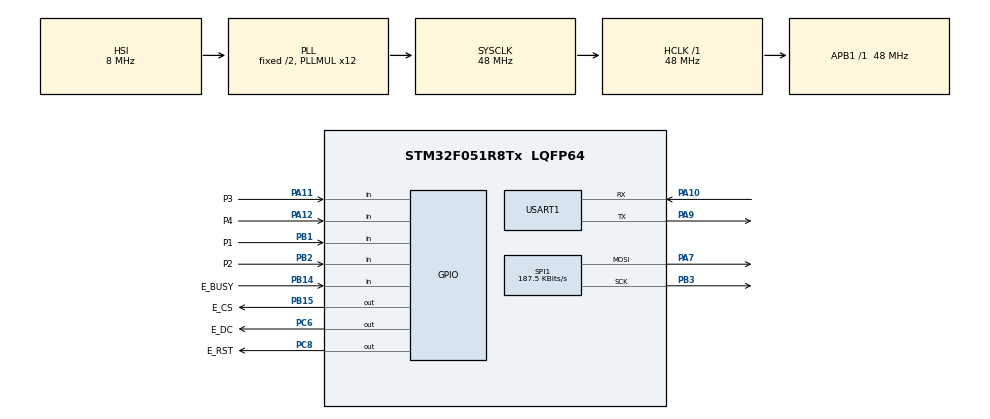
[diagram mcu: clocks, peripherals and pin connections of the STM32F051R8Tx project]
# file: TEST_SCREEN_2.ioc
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Mcu.Family=STM32F0
Mcu.Name=STM32F051R8Tx
Mcu.Package=LQFP64
PA10.Mode=Asynchronous
PA10.Signal=USART1_RX
PA11.GPIO_Label=P3
PA11.GPIO_PuPd=GPIO_PULLUP
PA11.Signal=GPIO_Input
PA12.GPIO_Label=P4
PA12.GPIO_PuPd=GPIO_PULLUP
PA12.Signal=GPIO_Input
PA13.GPIO_Label=TMS
PA13.Mode=Serial_Wire
PA13.Signal=SYS_SWDIO
PA14.GPIO_Label=SWCLK
PA14.Mode=Serial_Wire
PA14.Signal=SYS_SWCLK
PA2.Signal=USART2_TX
PA3.Signal=USART2_RX
PA7.Mode=TX_Only_Simplex_Unidirect_Master
PA7.Signal=SPI1_MOSI
PA9.Mode=Asynchronous
PA9.Signal=USART1_TX
PB1.GPIO_Label=P1
PB1.GPIO_PuPd=GPIO_PULLUP
PB1.Signal=GPIO_Input
PB14.GPIO_Label=E_BUSY
PB14.GPIO_PuPd=GPIO_PULLUP
PB14.Signal=GPIO_Input
PB15.GPIO_Label=E_CS
PB15.PinState=GPIO_PIN_SET
PB15.Signal=GPIO_Output
PB2.GPIO_Label=P2
PB2.GPIO_PuPd=GPIO_PULLUP
PB2.Signal=GPIO_Input
PB3.Mode=TX_Only_Simplex_Unidirect_Master
PB3.Signal=SPI1_SCK
PC14-OSC32_IN.Mode=LSE-External-Oscillator
PC14-OSC32_IN.Signal=RCC_OSC32_IN
PC15-OSC32_OUT.Mode=LSE-External-Oscillator
PC15-OSC32_OUT.Signal=RCC_OSC32_OUT
PC6.GPIO_Label=E_DC
PC6.Signal=GPIO_Output
PC8.GPIO_Label=E_RST
PC8.GPIO_Speed=GPIO_SPEED_FREQ_HIGH
PC8.PinState=GPIO_PIN_SET
PC8.Signal=GPIO_Output
PF0-OSC_IN.Mode=HSE-External-Oscillator
PF0-OSC_IN.Signal=RCC_OSC_IN
PF1-OSC_OUT.Mode=HSE-External-Oscillator
PF1-OSC_OUT.Signal=RCC_OSC_OUT
ProjectManager.HeapSize=0x2000
ProjectManager.StackSize=0x400
ProjectManager.TargetToolchain=STM32CubeIDE
RCC.AHBFreq_Value=48000000
RCC.APB1Freq_Value=48000000
RCC.APB1TimFreq_Value=48000000
RCC.HCLKFreq_Value=48000000
RCC.PLLMUL=RCC_PLL_MUL12
RCC.SYSCLKFreq_VALUE=48000000
RCC.SYSCLKSource=RCC_SYSCLKSOURCE_PLLCLK
SPI1.BaudRatePrescaler=SPI_BAUDRATEPRESCALER_256
SPI1.CalculateBaudRate=187.5 KBits/s
SPI1.DataSize=SPI_DATASIZE_8BIT
SPI1.Direction=SPI_DIRECTION_2LINES
SPI1.Mode=SPI_MODE_MASTER
SPI1.NSSPMode=SPI_NSS_PULSE_DISABLE
SPI1.VirtualType=VM_MASTER
USART1.VirtualMode-Asynchronous=VM_ASYNC
board=STM32F0DISCOVERY

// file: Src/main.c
/* USER CODE BEGIN Header */
/**
  ******************************************************************************
  * @file           : main.c
  * @brief          : Main program body
  ******************************************************************************
  * @attention
  *
  * <h2><center>&copy; Copyright (c) 2020 STMicroelectronics.
  * All rights reserved.</center></h2>
  *
  * This software component is licensed by ST under BSD 3-Clause license,
  * the "License"; You may not use this file except in compliance with the
  * License. You may obtain a copy of the License at:
  *                        opensource.org/licenses/BSD-3-Clause
  *
  ******************************************************************************
  */
/* USER CODE END Header */
//#include "tupian.h"

const unsigned char qie[] = {
		1,1,1,1,1,1,1,1,1,1,1,1,1,1,1,1,1,1,1,1,1,1,1,1,1,1,1,1,1,1,1,1,1,1,1,1,1,1,1,1,1,1,1,1,1,1,1,1,1,1,1,1,1,1,1,1,1,1,1,1,1,1,1,1,1,1,1,1,1,1,1,1,1,1,1,1,1,1,1,1,1,1,1,1,1,1,1,1,1,1,1,1,1,1,1,1,1,1,1,1,1,1,1,1,1,1,1,1,1,1,1,1,1,1,1,1,1,1,1,1,1,1,1,1,1,1,1,1,
		1,1,1,1,1,1,1,1,1,1,1,1,1,1,1,1,1,1,1,1,1,1,1,1,1,1,1,1,1,1,1,1,1,1,1,1,1,1,1,1,1,1,1,1,1,1,1,1,1,1,1,1,1,1,1,1,1,1,1,1,1,1,1,1,1,1,1,1,1,1,1,1,1,1,1,1,1,1,1,1,1,1,1,1,1,1,1,1,1,1,1,1,1,1,1,1,1,1,1,1,1,1,1,1,1,1,1,1,1,1,1,1,1,1,1,1,1,1,1,1,1,1,1,1,1,1,1,1,
		1,1,1,1,1,1,1,1,1,1,1,1,1,1,1,1,1,1,1,1,1,1,1,1,1,1,1,1,1,1,1,1,1,1,1,1,1,1,1,1,1,1,1,1,1,1,1,1,1,1,1,1,1,1,1,1,1,1,1,1,1,1,1,1,1,1,1,1,1,1,1,1,1,1,1,1,1,1,1,1,1,1,1,1,1,1,1,1,1,1,1,1,1,1,1,1,1,1,1,1,1,1,1,1,1,1,1,1,1,1,1,1,1,1,1,1,1,1,1,1,1,1,1,1,1,1,1,1,
		1,1,1,1,1,1,1,1,1,1,1,1,1,1,1,1,1,1,1,1,1,1,1,0,0,0,0,0,0,0,0,0,0,0,0,0,0,0,0,0,0,0,1,1,0,0,1,1,1,1,1,1,1,1,1,1,1,1,1,1,1,1,1,1,1,1,1,1,1,1,1,1,1,1,1,1,1,1,1,1,1,1,1,1,1,1,1,1,1,1,1,1,1,1,1,1,1,1,1,1,1,1,1,1,1,1,1,1,1,1,1,1,1,1,1,1,1,1,1,1,1,1,1,1,1,1,1,1,
		1,1,1,1,1,1,1,1,1,1,1,1,1,1,1,1,1,1,1,1,1,1,1,1,1,1,1,1,1,1,1,1,1,1,1,1,1,1,1,1,1,1,1,1,0,0,1,1,1,1,1,1,1,1,1,1,1,1,1,1,1,1,1,1,1,1,1,1,1,0,0,0,0,0,0,0,0,0,0,0,0,0,0,0,0,0,0,0,0,0,0,0,0,0,0,0,0,0,0,0,0,0,0,0,0,0,0,0,0,1,1,1,1,1,1,1,1,1,1,1,1,1,1,1,1,1,1,1,
		1,1,1,1,1,1,1,1,1,1,1,1,1,1,1,1,1,1,1,1,1,1,1,1,1,1,1,1,1,1,1,1,1,1,1,1,1,1,1,1,1,1,1,1,1,1,1,1,1,1,1,1,1,1,1,1,1,1,1,1,1,1,1,1,1,1,1,1,1,1,1,1,1,1,1,1,1,1,1,1,1,1,1,1,1,0,0,1,1,1,1,1,1,1,0,0,0,0,0,0,0,0,0,0,0,0,0,0,0,0,0,0,0,0,0,0,0,0,0,0,0,0,0,0,0,0,0,0,
		1,1,1,1,1,1,1,1,1,1,1,1,1,1,1,1,1,1,1,1,1,1,1,1,1,1,1,1,1,1,1,1,1,1,1,1,1,1,1,1,1,1,1,1,1,1,1,1,1,1,1,1,1,1,1,1,1,1,1,1,1,1,1,1,1,1,1,1,1,1,1,1,1,1,1,1,1,1,1,1,1,1,1,1,1,1,1,1,1,1,1,1,1,1,1,1,1,1,1,1,1,1,1,1,1,1,1,1,1,1,1,1,1,1,1,1,1,1,1,1,1,1,1,1,1,1,1,1,
		1,1,1,1,1,1,1,1,1,1,1,1,1,1,1,1,1,1,1,1,1,1,1,1,1,1,1,1,1,1,1,1,1,1,1,1,1,1,1,1,1,1,1,1,1,1,1,1,1,1,1,1,1,1,1,1,1,1,1,1,1,1,1,1,1,1,1,1,1,1,1,1,1,1,1,1,1,1,1,1,1,1,1,1,1,1,1,1,1,1,1,1,1,1,1,1,1,1,1,1,1,1,1,1,1,1,1,1,1,1,1,1,1,1,1,1,1,1,1,1,1,1,1,1,1,1,1,1,
		1,1,1,1,1,1,1,1,1,1,1,1,1,1,1,1,1,1,1,1,1,1,1,1,1,1,1,1,1,1,1,1,1,1,1,1,1,1,1,1,1,1,1,1,1,1,1,1,1,1,1,1,1,1,1,1,1,1,1,1,1,1,1,1,1,1,1,1,1,1,1,1,1,1,1,1,1,1,1,1,1,1,1,1,1,1,1,1,1,1,1,1,1,1,1,1,1,1,1,1,1,1,1,1,1,1,1,1,1,1,1,1,1,1,1,1,1,1,1,1,1,1,1,1,1,1,1,1,
		1,1,1,1,1,1,1,1,1,1,1,1,1,1,1,0,0,0,0,0,0,0,0,0,0,0,0,0,0,0,0,0,0,0,0,0,0,0,0,1,1,1,1,1,1,1,1,1,1,1,1,1,1,1,1,1,1,1,1,1,1,1,1,1,1,1,1,1,1,1,1,1,1,1,1,1,1,1,1,1,1,1,1,1,1,1,1,1,1,1,1,1,1,1,1,1,1,1,1,1,1,1,1,1,1,1,1,1,1,1,1,1,1,1,1,1,1,1,1,1,1,1,1,1,1,1,1,1,
		1,1,1,1,1,1,1,1,1,1,1,1,1,1,1,1,1,1,1,1,1,1,1,1,1,1,1,1,1,1,1,1,0,0,0,0,0,0,1,0,0,0,0,1,1,1,1,1,1,1,1,1,1,1,1,1,1,1,1,1,1,1,1,1,1,1,1,1,1,1,1,1,1,1,1,1,1,1,1,1,1,1,1,1,1,1,1,1,1,1,0,0,0,0,0,0,0,0,0,0,0,0,1,1,1,1,1,1,1,1,1,1,1,1,1,1,1,1,1,1,1,1,1,1,1,1,1,1,
		1,1,1,1,1,1,1,1,1,1,1,1,1,0,1,1,1,1,1,1,1,1,1,1,1,1,1,1,1,1,1,1,1,1,1,1,1,1,1,1,1,1,1,1,1,1,1,1,1,1,1,1,1,1,1,1,1,1,1,1,1,1,1,1,1,1,1,1,1,1,1,1,1,1,1,1,1,1,1,1,1,1,1,1,1,1,1,1,1,1,0,0,0,0,0,0,0,0,0,0,0,0,0,0,0,0,0,0,0,0,0,0,0,0,0,0,0,0,0,0,0,0,0,0,0,0,0,0,
		1,1,1,1,1,1,1,1,1,1,1,1,0,0,0,0,0,0,0,0,0,0,0,0,0,1,1,1,1,1,1,1,1,1,1,1,1,1,1,1,1,1,1,1,1,1,1,1,1,1,1,1,1,1,1,1,1,1,1,1,1,1,1,1,1,1,1,1,1,1,1,1,1,1,1,1,1,1,1,1,1,1,1,1,1,1,1,1,1,1,1,1,1,1,1,1,1,1,1,1,1,1,1,1,1,1,1,1,1,0,0,0,0,0,0,0,0,0,0,0,0,0,0,0,0,0,0,0,
		1,1,1,1,1,1,1,1,1,1,1,1,1,0,0,0,0,0,0,0,0,0,0,0,0,0,0,0,0,0,0,0,0,0,0,0,0,1,1,1,1,1,1,1,1,1,1,1,1,1,1,1,1,1,1,1,1,1,1,1,1,1,1,1,1,1,1,1,1,1,1,1,1,1,1,1,1,1,1,1,1,1,1,1,1,1,1,1,1,1,1,1,1,1,1,1,1,1,1,1,1,1,1,1,1,1,1,1,1,1,1,1,1,1,1,1,1,1,1,1,1,1,1,1,1,1,1,1,
		1,1,1,1,1,1,1,1,1,1,1,1,1,1,1,1,1,1,1,1,1,1,1,1,1,1,1,1,1,1,1,1,1,1,1,1,1,1,1,1,1,1,1,1,1,1,1,1,1,1,1,1,1,1,1,1,1,1,1,1,1,1,1,1,1,1,1,1,1,1,1,1,1,1,1,1,1,1,1,1,1,1,1,1,1,1,1,1,1,1,1,1,0,0,0,0,0,0,0,0,0,0,0,0,0,0,0,0,0,0,0,0,0,0,0,0,0,0,0,0,0,0,0,0,0,0,0,0,
		1,1,1,1,1,1,1,1,1,1,1,1,1,1,1,1,1,1,1,1,1,1,1,1,1,1,1,1,1,1,1,1,1,1,1,1,1,1,1,1,1,1,1,1,1,1,1,1,1,1,1,1,1,1,1,1,1,1,1,1,1,1,1,1,1,1,1,1,1,1,1,1,1,1,1,1,1,1,1,1,1,1,1,1,1,1,1,1,1,1,1,1,1,1,1,1,0,0,0,0,0,0,0,0,0,0,0,0,0,0,0,0,0,0,0,0,0,0,0,0,0,0,0,0,0,0,0,0,
		1,1,1,1,1,1,1,1,1,1,1,1,1,1,1,1,1,1,1,1,1,1,1,1,1,1,1,1,1,1,1,1,1,1,1,1,1,1,1,1,1,1,1,1,1,1,1,1,1,1,1,1,1,1,1,1,1,1,1,1,1,1,1,1,1,1,1,1,1,1,1,1,1,1,1,1,1,1,1,1,1,1,1,1,1,1,1,1,1,1,1,1,1,1,1,1,1,1,1,1,1,1,1,1,1,1,1,1,1,1,1,1,1,1,1,1,1,1,1,1,1,1,1,1,1,1,1,1,
		1,1,1,1,1,1,1,1,1,1,1,1,1,1,1,1,1,1,1,1,1,1,1,1,1,1,1,1,1,1,1,1,1,1,1,1,1,1,1,1,1,1,1,1,1,1,1,1,1,1,1,1,1,1,1,1,1,1,1,1,1,1,1,1,1,1,1,1,1,1,1,1,1,1,1,1,1,1,1,1,1,1,1,1,1,1,1,1,1,1,1,1,1,1,1,1,1,1,1,1,1,1,1,1,1,1,1,1,1,1,1,1,1,1,1,1,1,1,1,1,1,1,1,1,1,1,1,1,
		1,1,1,1,1,1,1,1,1,1,1,1,1,1,1,1,1,1,1,1,1,1,1,1,1,1,1,1,1,1,1,1,1,1,1,1,1,1,1,1,1,1,1,1,1,1,1,1,1,1,1,1,1,1,1,1,1,1,1,1,1,1,1,1,1,1,1,1,1,1,1,1,1,1,1,1,1,1,1,1,1,1,1,1,1,1,1,1,1,1,1,1,1,1,1,1,1,1,1,1,1,1,1,1,1,1,1,1,1,1,1,1,1,1,1,1,1,1,1,1,1,1,1,1,1,1,1,1,
		1,1,1,1,1,1,1,1,1,1,1,1,1,1,1,1,1,1,1,1,1,1,1,1,1,1,1,1,1,1,1,1,1,1,1,1,1,1,1,1,1,1,1,1,1,1,1,1,1,1,1,1,1,1,1,1,1,1,1,1,1,1,1,1,1,1,1,1,1,1,1,1,1,1,1,1,1,1,1,1,1,1,1,1,1,1,1,1,1,1,1,1,1,1,1,1,1,1,1,1,1,1,1,1,1,1,1,1,1,1,1,1,1,1,1,1,1,1,1,1,1,1,1,1,1,1,1,1,
		1,1,1,1,1,1,1,1,1,1,1,1,1,1,1,1,1,1,1,1,1,1,1,1,1,1,1,1,1,1,1,1,1,1,1,1,1,1,1,1,1,1,1,1,1,1,1,1,1,1,1,1,1,1,1,1,1,1,1,1,1,1,1,1,1,1,1,1,1,1,1,1,1,1,1,1,1,1,1,1,1,1,1,1,1,1,1,1,1,1,1,1,1,1,1,1,1,1,1,1,1,1,1,1,1,1,1,1,1,1,1,1,1,1,1,1,1,1,1,1,1,1,1,1,1,1,1,1,
		1,1,1,1,1,1,1,1,1,1,1,1,1,1,1,1,1,1,1,1,1,1,1,1,1,1,1,1,1,1,1,1,1,1,1,1,1,1,1,1,1,1,1,1,1,1,1,1,1,1,1,1,1,1,1,1,1,1,1,1,1,1,1,1,1,1,1,1,1,1,1,1,1,1,1,1,1,1,1,1,1,1,1,1,1,1,1,1,1,1,1,1,1,1,1,1,1,1,1,1,1,1,1,1,1,1,1,1,1,1,1,1,1,1,1,1,1,1,1,1,1,1,1,1,1,1,1,1,
		1,1,1,1,1,1,1,1,1,1,1,1,1,1,1,1,1,1,1,1,1,1,1,1,1,1,1,1,1,1,1,1,1,1,1,1,1,1,1,1,1,1,1,1,1,1,1,1,1,1,1,1,1,1,1,1,1,1,1,1,1,1,1,1,1,1,1,1,1,1,1,1,1,1,1,1,1,1,1,1,1,1,1,1,1,1,1,1,1,1,1,1,1,1,1,1,1,1,1,1,1,1,1,1,1,1,1,1,1,1,1,1,1,1,1,1,1,1,1,1,1,1,1,1,1,1,1,1,
		1,1,1,1,1,1,1,1,1,1,1,1,1,1,1,1,1,1,1,1,1,1,1,1,1,1,1,1,1,1,1,1,1,1,1,1,1,1,1,1,1,1,1,1,1,1,1,1,1,1,1,1,1,1,1,1,1,1,1,1,1,1,1,1,1,1,1,1,1,1,1,1,1,1,1,1,1,1,1,1,1,1,1,1,1,1,1,1,1,1,1,1,1,1,1,1,1,1,1,1,1,1,1,1,1,1,1,1,1,1,1,1,1,1,1,1,1,1,1,1,1,1,1,1,1,1,1,1,
		1,1,1,1,1,1,1,1,1,1,1,1,1,1,1,1,1,1,1,1,1,1,1,1,1,1,1,1,1,1,1,1,1,1,1,1,1,1,1,1,1,1,1,1,1,1,1,1,1,1,1,1,1,1,1,1,1,1,1,1,1,1,1,1,1,1,1,1,1,1,1,1,1,1,1,1,1,1,1,1,1,1,1,1,1,1,1,1,1,1,1,1,1,1,1,1,1,1,1,1,1,1,1,1,1,1,1,1,1,1,1,1,1,1,1,1,1,1,1,1,1,1,1,1,1,1,1,1,
		1,1,1,1,1,1,1,1,1,1,1,1,1,1,1,1,1,1,1,1,1,1,1,1,1,1,1,1,1,1,1,1,1,1,1,1,1,1,1,1,1,1,1,1,1,1,1,1,1,1,1,1,1,1,1,1,1,1,1,1,1,1,1,1,1,1,1,1,1,1,1,1,1,1,1,1,1,1,1,1,1,1,1,1,1,1,1,1,1,1,1,1,1,1,1,1,1,1,1,1,1,1,1,1,1,1,1,1,1,1,1,1,1,1,1,1,1,1,1,1,1,1,1,1,1,1,1,1,
		1,1,1,1,1,1,1,1,1,1,1,1,1,1,1,1,1,1,1,1,1,1,1,1,1,1,1,1,1,1,1,1,1,1,1,1,1,1,1,1,1,1,1,1,1,1,1,1,1,1,1,1,1,1,1,1,1,1,1,1,1,1,1,1,1,1,1,1,1,1,1,1,1,1,1,1,1,1,1,1,1,1,1,1,1,1,1,1,1,1,1,1,1,1,1,1,1,1,1,1,1,1,1,1,1,1,1,1,1,1,1,1,1,1,1,1,1,1,1,1,1,1,1,1,1,1,1,1,
		0,0,0,0,1,0,0,1,1,1,1,1,1,1,1,1,1,1,1,1,1,1,1,1,1,1,1,1,1,1,1,1,1,1,1,1,1,1,1,1,1,1,1,1,1,1,1,1,1,1,1,1,1,1,1,1,1,1,1,1,1,1,1,1,1,1,1,1,1,1,1,1,1,1,1,1,1,1,1,1,1,1,1,1,1,1,1,1,1,1,1,1,1,1,1,1,1,1,1,1,1,1,1,1,1,1,1,1,1,1,1,1,1,1,1,1,1,1,1,1,1,1,1,1,1,1,1,1,
		0,1,1,1,1,1,1,1,1,1,1,1,1,1,1,1,1,1,1,1,1,1,1,1,1,1,1,1,1,1,1,1,1,1,1,1,1,1,1,1,1,1,1,1,1,1,1,1,1,1,1,1,1,1,1,1,1,1,1,1,1,1,1,1,1,1,1,1,1,1,1,1,1,1,1,1,1,1,1,1,1,1,1,1,1,1,1,1,1,1,1,1,1,1,1,1,1,1,1,1,1,1,1,1,1,1,1,1,1,1,1,1,1,1,1,1,1,1,1,1,1,1,1,1,1,1,1,1,
		1,1,1,1,1,1,1,1,1,1,1,1,1,1,1,1,1,1,1,1,1,1,1,1,1,1,1,1,1,1,1,1,1,1,1,1,1,1,1,1,1,1,1,1,1,1,1,1,1,1,1,1,1,1,1,1,1,1,1,1,1,1,1,1,1,1,1,1,1,1,1,1,1,1,1,1,1,1,1,1,1,1,1,1,1,1,1,1,1,1,1,1,1,1,1,1,1,1,1,1,1,1,1,1,1,1,1,1,1,1,1,1,1,1,1,1,1,1,1,1,1,1,1,1,1,1,1,1,
		1,1,1,1,1,1,1,1,1,1,1,1,1,1,1,1,1,1,1,1,1,1,1,1,1,1,1,1,1,1,1,1,1,1,1,1,1,1,1,1,1,1,1,1,1,1,1,1,1,1,1,1,1,1,1,1,1,1,1,1,1,1,1,1,1,1,1,1,1,1,1,1,1,1,1,1,1,1,1,1,1,1,1,1,1,1,1,1,1,1,1,1,1,1,1,1,1,1,1,1,1,1,1,1,1,1,1,1,1,1,1,1,1,1,1,1,1,1,1,1,1,1,1,1,1,1,1,1,
		1,1,1,1,1,1,1,1,1,1,1,1,1,1,1,1,1,1,1,1,1,1,1,1,1,1,1,1,1,1,1,1,1,1,1,1,1,1,1,1,1,1,1,1,1,1,1,1,1,1,1,1,1,1,1,1,1,1,1,1,1,1,1,1,1,1,1,1,1,1,1,1,1,1,1,1,1,1,1,1,1,1,1,1,1,1,1,1,1,1,1,1,1,1,1,1,1,1,1,1,1,1,1,1,1,1,1,1,1,1,1,1,1,1,1,1,1,1,1,1,1,1,1,1,1,1,1,1,
		1,1,1,1,1,1,1,1,1,1,1,1,1,1,1,1,1,1,1,1,1,1,1,1,1,1,1,1,1,1,1,1,1,1,1,1,1,1,1,1,1,1,1,1,1,1,1,1,1,1,1,1,1,1,1,1,1,1,1,1,1,1,1,1,1,1,1,1,1,1,1,1,1,1,1,1,1,1,1,1,1,1,1,1,1,1,1,1,1,1,1,1,1,1,1,1,1,1,1,1,1,1,1,1,1,1,1,1,1,1,1,1,1,1,1,1,1,1,1,1,1,1,1,1,1,1,1,1,
		1,1,1,1,1,1,1,1,1,1,1,1,1,1,1,1,1,1,1,1,1,1,1,1,1,1,1,1,1,1,1,1,1,1,1,1,1,1,1,1,1,1,1,1,1,1,1,1,1,1,1,1,1,1,1,1,1,1,1,1,1,1,1,1,1,1,1,1,1,1,1,1,1,1,1,1,1,1,1,1,1,1,1,1,1,1,1,1,1,1,1,1,1,1,1,1,1,1,1,1,1,1,1,1,1,1,1,1,1,1,1,1,1,1,1,1,1,1,1,1,1,1,1,1,1,1,1,1,
		1,1,1,1,1,1,1,1,1,1,1,1,1,1,1,1,1,1,1,1,1,1,1,1,1,1,1,1,1,1,1,1,1,1,1,1,1,1,1,1,1,1,1,1,1,1,1,1,1,1,1,1,1,1,1,1,1,1,1,1,1,1,1,1,1,1,1,1,1,1,1,1,1,1,1,1,1,1,1,1,1,1,1,1,1,1,1,1,1,1,1,1,1,1,1,1,1,1,1,1,1,1,1,1,1,1,1,1,1,1,1,1,1,1,1,1,1,1,1,1,1,1,1,1,1,1,1,1,
		1,1,1,1,1,1,1,1,1,1,1,1,1,1,1,1,1,1,1,1,1,1,1,1,1,1,1,1,1,1,1,1,1,1,1,1,1,1,1,1,1,1,1,1,1,1,1,1,1,1,1,1,1,1,1,1,1,1,1,1,1,1,1,1,1,1,1,1,1,1,1,1,1,1,1,1,1,1,1,1,1,1,1,1,1,1,1,1,1,1,1,1,1,1,1,1,1,1,1,1,1,1,1,1,1,1,1,1,1,1,1,1,1,1,1,1,1,1,1,1,1,1,1,1,1,1,1,1,
		1,1,1,1,1,1,1,1,1,1,1,1,1,1,1,1,1,1,1,1,1,1,1,1,1,1,1,1,1,1,1,1,1,1,1,1,1,1,1,1,1,1,1,1,1,1,1,1,1,1,1,1,1,1,1,1,1,1,1,1,1,1,1,1,1,1,1,1,1,1,1,1,1,1,1,1,1,1,1,1,1,1,1,1,1,1,1,1,1,1,1,1,1,1,1,1,1,1,1,1,1,1,1,1,1,1,1,1,1,1,1,1,1,1,1,1,1,1,1,1,1,1,1,1,1,1,1,1,
		1,1,1,1,1,1,1,1,1,1,1,1,1,1,1,1,1,1,1,1,1,1,1,1,1,1,1,1,1,1,1,1,1,1,1,1,1,1,1,1,1,1,1,1,1,1,1,1,1,1,1,1,1,1,1,1,1,1,1,1,1,1,1,1,1,1,1,1,1,1,1,1,1,1,1,1,1,1,1,1,1,1,1,1,1,1,1,1,1,1,1,1,1,1,1,1,1,1,1,1,1,1,1,1,1,1,1,1,1,1,1,1,1,1,1,1,1,1,1,1,1,1,1,1,1,1,1,1,
		1,1,1,1,1,1,1,1,1,1,1,1,1,1,1,1,1,1,1,1,1,1,1,1,1,1,1,1,1,1,1,1,1,1,1,1,1,1,1,1,1,1,1,1,1,1,1,1,1,1,1,1,1,1,1,1,1,1,1,1,1,1,1,1,1,1,1,1,1,1,1,1,1,1,1,1,1,1,1,1,1,1,1,1,1,1,1,1,1,1,1,1,1,1,1,1,1,1,1,1,1,1,1,1,1,1,1,1,1,1,1,1,1,1,1,1,1,1,1,1,1,1,1,1,1,1,1,1,
		1,1,1,1,1,1,1,1,1,1,1,1,1,1,1,1,1,1,1,1,1,1,1,1,1,1,1,1,1,1,1,1,1,1,1,1,1,1,1,1,1,1,1,1,1,1,1,1,1,1,1,1,1,1,1,1,1,1,1,1,1,1,1,1,1,1,1,1,1,1,1,1,0,1,1,1,1,1,1,1,1,1,1,1,1,1,1,1,1,1,1,1,1,1,1,1,1,1,1,1,1,1,1,1,1,1,1,1,1,1,1,1,1,1,1,1,1,1,1,1,1,1,1,1,1,1,1,1,
		1,1,1,1,1,1,1,1,1,1,1,1,1,1,1,1,1,1,1,1,1,1,1,1,1,1,1,1,1,1,1,1,1,1,1,1,1,1,1,1,1,1,1,1,1,1,1,1,1,1,1,1,1,1,1,1,1,1,1,1,1,1,1,0,1,1,1,0,0,0,0,0,0,0,0,0,1,1,1,1,1,1,1,1,1,1,1,1,1,1,1,1,1,1,1,1,1,1,1,1,1,1,1,1,1,1,1,1,1,1,1,1,1,1,1,1,1,1,1,1,1,1,1,1,1,1,1,1,
		1,1,1,1,1,1,1,1,1,1,1,1,1,1,1,1,1,1,1,1,1,1,1,1,1,1,1,1,1,1,1,1,1,1,1,1,1,1,1,1,1,1,1,1,1,1,1,1,1,1,1,1,1,1,1,1,1,1,1,1,0,0,0,0,0,0,0,0,0,0,0,0,0,0,0,0,0,0,1,1,1,1,1,1,1,1,1,1,1,1,1,1,1,1,1,1,1,1,1,1,1,1,1,1,1,1,1,1,1,1,1,1,1,1,1,1,1,1,1,1,1,1,1,1,1,1,1,1,
		1,1,1,1,1,1,1,1,1,1,1,1,1,1,1,0,0,0,0,0,0,0,1,1,1,1,1,1,1,1,1,1,1,1,1,1,1,1,1,1,1,1,1,1,1,1,1,1,1,1,1,1,1,1,1,0,0,0,0,0,0,0,0,0,0,0,0,0,0,0,0,0,0,0,0,0,0,0,0,0,1,1,1,1,1,1,1,1,1,1,1,1,1,1,1,1,1,1,1,1,1,1,1,1,1,1,1,1,1,1,1,1,1,1,1,1,1,1,1,1,1,1,1,1,1,1,1,1,
		1,1,1,1,1,1,1,1,1,1,1,1,1,1,0,0,1,1,1,1,1,1,1,1,1,1,1,1,1,1,1,1,1,1,1,1,1,1,1,1,1,1,1,1,1,1,1,1,1,1,0,0,0,0,0,0,0,0,0,0,0,0,0,0,0,0,0,0,0,0,0,0,0,0,0,0,0,0,0,0,0,0,1,1,1,1,1,1,1,1,1,1,1,1,1,1,1,1,1,1,1,1,1,1,1,1,0,0,0,0,0,0,0,0,0,0,0,0,0,0,0,0,0,0,0,0,0,0,
		1,1,1,1,1,1,1,1,1,1,1,1,1,1,0,0,1,1,1,1,1,1,1,1,1,1,1,1,1,1,1,1,1,1,1,1,1,1,1,1,1,1,1,1,1,1,1,1,0,0,0,0,0,0,0,0,0,0,0,0,0,0,0,0,0,0,0,0,0,0,0,0,0,0,0,0,0,0,0,0,0,0,1,1,1,1,1,1,1,1,1,1,1,1,1,1,1,1,1,1,1,1,1,1,1,1,1,1,1,1,1,1,1,1,1,1,1,1,1,1,1,1,1,1,1,1,0,0,
		1,1,1,1,1,1,1,1,1,1,1,1,1,1,1,0,1,1,1,1,1,1,1,1,1,1,1,1,1,1,1,1,1,1,1,1,1,1,1,1,1,1,1,1,1,1,0,0,0,0,0,0,0,0,0,0,0,0,0,0,0,0,0,0,0,0,0,0,0,0,0,0,0,0,0,0,0,0,0,0,0,0,0,1,1,1,1,1,1,1,1,1,1,1,1,1,1,1,1,1,1,1,1,1,1,1,1,1,1,1,1,1,1,1,1,1,1,1,1,1,1,1,1,1,1,1,1,1,
		1,1,1,1,1,1,1,1,1,1,1,1,1,1,1,1,1,1,1,1,1,1,1,1,1,1,1,1,1,1,1,1,1,1,1,1,1,1,1,1,1,1,1,1,0,0,0,0,0,0,0,0,0,0,0,0,0,0,0,0,0,0,0,0,0,0,0,0,0,0,0,0,0,0,0,0,0,0,0,0,0,0,0,1,1,1,1,1,1,1,1,1,1,1,1,1,1,1,1,1,1,1,1,1,1,1,1,1,1,1,1,1,1,1,1,1,1,1,1,1,1,1,1,1,1,1,1,1,
		1,1,1,1,1,1,1,1,1,1,1,1,1,1,1,1,1,1,1,1,1,1,1,1,1,1,1,1,1,1,1,1,1,1,1,1,1,1,1,1,1,1,1,1,0,0,0,0,0,0,0,0,0,0,0,0,0,0,0,0,0,0,0,0,0,0,0,0,0,0,0,0,0,0,0,0,0,0,0,0,0,0,0,0,1,1,1,1,1,1,1,1,1,1,1,1,1,1,1,1,1,1,1,1,1,1,1,1,1,1,1,1,1,1,1,1,1,1,1,1,1,1,1,1,1,1,1,1,
		1,1,1,1,1,1,1,1,1,1,1,1,1,1,1,1,1,1,1,1,1,1,1,1,1,1,1,1,1,1,1,1,1,1,1,1,1,1,1,1,1,1,1,0,0,0,0,0,0,0,0,0,0,0,0,0,0,0,0,0,0,0,0,0,0,0,0,0,0,0,0,0,0,0,0,0,0,0,0,0,0,0,0,0,0,1,1,1,1,1,1,1,1,1,1,1,1,1,1,1,1,1,1,1,1,1,1,1,1,1,1,1,1,1,1,1,1,1,1,1,1,1,1,1,1,1,1,1,
		1,1,1,1,1,1,1,1,1,1,1,1,1,1,1,1,1,1,1,1,1,1,1,1,1,1,1,1,1,1,1,1,1,1,1,1,1,1,1,1,1,1,0,0,0,0,0,0,0,0,0,0,0,0,0,0,0,0,0,0,0,0,0,0,0,0,0,0,0,0,0,0,0,0,0,0,0,0,0,0,0,0,0,0,0,1,1,1,1,1,1,1,1,1,1,1,1,1,1,1,1,1,1,1,1,1,1,1,1,1,1,1,1,1,1,1,1,1,1,1,1,1,1,1,1,1,1,1,
		1,1,1,1,1,1,1,1,1,1,1,1,1,1,1,1,1,1,1,1,1,1,1,1,1,1,1,1,1,1,1,1,1,1,1,1,1,1,1,1,0,0,0,0,0,0,0,0,0,0,0,0,0,0,0,0,0,0,0,0,0,0,0,0,0,0,0,0,0,0,0,0,0,0,0,0,0,0,0,0,0,0,0,0,0,0,1,1,1,1,1,1,1,1,1,1,1,1,1,1,1,1,1,1,1,1,1,1,1,1,1,1,1,1,1,1,1,1,1,1,1,1,1,1,1,1,1,1,
		1,1,1,1,1,1,1,1,1,1,1,1,1,1,1,1,1,1,1,1,1,1,1,1,1,1,1,1,1,1,1,1,1,1,1,1,1,1,1,1,0,0,0,0,0,0,0,0,0,0,0,0,0,0,0,0,0,0,0,0,0,0,0,0,0,0,0,0,0,0,0,0,0,0,0,0,0,0,0,0,0,0,0,0,0,0,0,0,1,1,1,1,1,1,1,1,1,1,1,1,1,1,1,1,1,1,1,1,1,1,1,1,1,1,1,1,1,1,1,1,1,1,1,1,1,1,1,1,
		1,1,1,1,1,1,1,1,1,1,1,1,1,1,1,1,1,1,1,1,1,1,1,1,1,1,1,1,1,1,1,1,1,1,1,1,1,1,1,0,0,0,0,0,0,0,0,0,0,0,0,0,0,0,0,0,0,0,0,0,0,0,0,0,0,0,0,0,0,0,0,0,0,0,0,0,0,0,0,0,0,0,0,0,0,0,0,0,0,0,0,1,1,1,1,1,1,1,1,1,1,1,1,1,1,1,1,1,1,1,1,1,1,1,1,1,1,1,1,1,1,1,1,1,1,1,1,1,
		1,1,1,1,1,1,1,1,1,1,1,1,1,1,1,1,1,1,1,1,1,1,1,1,1,1,1,1,1,1,1,1,1,1,1,1,1,1,0,0,0,0,0,0,0,0,0,0,0,0,0,0,0,0,0,0,0,0,0,0,0,0,0,0,0,0,0,0,0,0,0,0,0,0,0,0,0,0,0,0,0,0,0,0,0,0,0,0,0,0,0,1,1,1,1,1,1,1,1,1,1,1,1,1,1,1,1,1,1,1,1,1,1,1,1,1,1,1,1,1,1,1,1,1,1,1,1,1,
		1,1,1,1,1,1,1,1,1,1,1,1,1,1,1,1,1,1,1,1,1,1,1,1,1,1,1,1,1,1,1,1,1,1,1,1,0,0,0,0,0,0,0,0,0,0,0,0,0,0,0,0,0,0,0,0,0,0,0,0,0,0,0,0,0,0,0,0,0,0,0,0,0,0,0,0,0,0,0,0,0,0,0,0,0,0,0,0,0,0,0,0,0,1,1,1,1,1,1,1,1,1,1,1,1,1,1,1,1,1,1,1,1,1,1,1,1,1,1,1,1,1,1,1,1,1,1,1,
		1,1,1,1,1,1,1,1,1,1,1,1,1,1,1,1,1,1,1,1,1,1,1,1,1,1,1,1,1,1,1,1,1,1,1,1,0,0,0,0,0,0,0,0,0,0,0,0,0,0,0,0,0,0,0,0,0,0,0,0,0,0,0,0,0,0,0,0,0,0,0,0,0,0,0,0,0,0,0,0,0,0,0,0,0,0,0,0,0,0,0,0,0,0,1,1,1,1,1,1,1,1,1,1,1,1,1,1,1,1,1,1,1,1,1,1,1,1,1,1,1,1,1,1,1,1,1,1,
		1,1,1,1,1,1,1,1,1,1,1,1,1,1,1,1,1,1,1,1,1,1,1,1,1,1,1,1,1,1,1,1,1,1,1,0,0,0,0,0,0,0,0,0,0,0,0,0,0,0,0,0,0,0,0,0,0,0,0,0,0,0,0,0,0,0,0,0,0,0,0,0,0,0,0,0,0,0,0,0,0,0,0,0,0,0,0,0,0,0,0,0,0,0,1,1,1,1,1,1,1,1,1,1,1,1,1,1,1,1,1,1,1,1,1,1,1,1,1,1,1,1,1,1,1,1,1,1,
		1,1,1,1,1,1,1,1,1,1,1,1,1,1,1,1,1,1,1,1,1,1,1,1,1,1,1,1,1,1,1,1,1,1,1,0,0,0,0,0,0,0,0,0,0,0,0,0,0,0,0,0,0,0,0,0,0,0,0,0,0,0,0,0,0,0,0,0,0,0,0,0,0,0,0,0,0,0,0,0,0,0,0,0,0,0,0,0,0,0,0,0,0,0,0,1,1,1,1,1,1,1,1,1,1,1,1,1,1,1,1,1,1,1,1,1,1,1,1,1,1,1,1,1,1,1,1,1,
		1,1,1,1,1,1,1,1,1,1,1,1,1,1,1,1,1,1,1,1,1,1,1,1,1,1,1,1,1,1,1,1,1,1,0,0,0,0,0,0,0,0,0,0,0,0,0,0,0,0,0,0,0,0,0,0,0,0,0,0,0,0,0,0,0,0,0,0,0,0,0,0,0,0,0,0,0,0,0,0,0,0,0,0,0,0,0,0,0,0,0,0,0,0,0,0,1,1,1,1,1,1,1,1,1,1,1,1,1,1,1,1,1,1,1,1,1,1,1,1,1,1,1,1,1,1,1,1,
		1,1,1,1,1,1,1,1,1,1,1,1,1,1,1,1,1,1,1,1,1,1,1,1,1,1,1,1,1,1,1,1,1,1,0,0,0,0,0,0,0,0,0,0,0,0,0,0,0,0,0,0,0,0,0,0,0,0,0,0,0,0,0,0,0,0,0,0,0,0,0,0,0,0,0,0,0,0,0,0,0,0,0,0,0,0,0,0,0,0,0,0,0,0,0,0,1,1,1,1,1,1,1,1,1,1,1,1,1,1,1,1,1,1,1,1,1,1,1,1,1,1,1,1,1,1,1,1,
		1,1,1,1,1,1,1,1,1,1,1,1,1,1,1,1,1,1,1,1,1,1,1,1,1,1,1,1,1,1,1,1,1,1,0,0,0,0,0,0,0,0,0,0,0,0,0,0,0,0,0,0,0,0,0,0,0,0,0,0,0,0,0,0,0,0,0,0,0,0,0,0,0,0,0,0,0,0,0,0,0,0,0,0,0,0,0,0,0,0,0,0,0,0,0,0,0,1,1,1,1,1,1,1,1,1,1,1,1,1,1,1,1,1,1,1,1,1,1,1,1,1,1,1,1,1,1,1,
		1,1,1,1,1,1,1,1,1,1,1,1,1,1,1,1,1,1,1,1,1,1,1,1,1,1,1,1,1,1,1,1,1,1,0,0,0,0,0,0,0,0,0,0,0,0,0,0,0,0,0,0,0,0,0,0,0,0,0,0,0,0,0,0,0,0,0,0,0,0,0,0,0,0,0,0,0,0,0,0,0,0,0,0,0,0,0,0,0,0,0,0,0,0,0,0,0,0,1,1,1,1,1,1,1,1,1,1,1,1,1,1,1,1,1,1,1,1,1,1,1,1,1,1,1,1,1,1,
		1,1,1,1,1,1,1,1,1,1,1,1,1,1,1,1,1,1,1,1,1,1,1,1,1,1,1,1,1,1,1,1,1,0,0,0,0,0,0,0,0,0,0,0,0,0,0,0,0,0,0,0,0,0,0,0,0,0,0,0,0,0,0,0,0,0,0,0,0,0,0,0,0,0,0,0,0,0,0,0,0,0,0,0,0,0,0,0,0,0,0,0,0,0,0,0,0,0,1,1,1,1,1,1,1,1,1,1,1,1,1,1,1,1,1,1,1,1,1,1,1,1,1,1,1,1,1,1,
		1,1,1,1,1,1,1,1,1,1,1,1,1,1,1,1,1,1,1,1,1,1,1,1,1,1,1,1,1,1,1,1,1,0,0,0,0,0,0,0,0,0,0,0,0,0,0,0,0,0,0,0,0,0,0,0,0,0,0,0,0,0,0,0,0,0,0,0,0,0,0,0,0,0,0,0,0,1,1,1,0,0,0,0,0,0,0,0,0,0,0,0,0,0,0,0,0,0,1,1,1,1,1,1,1,1,1,1,1,1,1,1,1,1,1,1,1,1,1,1,1,1,1,1,1,1,1,1,
		1,1,1,1,1,1,1,1,1,1,1,1,1,1,1,1,1,1,1,1,1,1,1,1,1,1,1,1,1,1,1,1,1,0,0,0,0,0,0,0,0,0,0,0,0,0,0,0,0,0,0,0,0,0,0,0,0,0,0,0,0,0,0,0,0,0,0,0,0,0,1,1,1,1,1,1,1,1,1,1,1,1,1,0,0,0,0,0,0,0,0,0,0,0,0,0,0,0,1,1,1,1,1,1,1,1,1,1,1,1,1,1,1,1,1,1,1,1,1,1,1,1,1,1,1,1,1,1,
		1,1,1,1,1,1,1,1,1,1,1,1,1,1,1,1,1,1,1,1,1,1,1,1,1,1,1,1,1,1,1,1,1,0,0,0,0,0,0,0,0,0,0,1,1,1,1,1,1,1,1,0,0,0,0,0,0,0,0,0,0,0,0,0,0,0,0,1,1,1,1,1,1,1,1,1,1,1,1,1,1,1,1,1,1,0,0,0,0,0,0,0,0,0,0,0,0,0,0,1,1,1,1,1,1,1,1,1,1,1,1,1,1,1,1,1,1,1,1,1,1,1,1,1,1,1,1,1,
		1,1,1,1,1,1,1,1,1,1,1,1,1,1,1,1,1,1,1,1,1,1,1,1,1,1,1,1,1,1,1,1,0,0,0,0,0,0,0,0,0,1,1,1,1,1,1,1,1,1,1,1,1,1,1,1,1,0,0,0,0,0,0,0,1,1,1,1,1,1,1,1,1,1,1,1,1,1,1,1,1,1,1,1,1,0,0,0,0,0,0,0,0,0,0,0,0,0,0,1,1,1,1,1,1,1,1,1,1,1,1,1,1,1,1,1,1,1,1,1,1,1,1,1,1,1,1,1,
		1,1,1,1,1,1,1,1,1,1,1,1,1,1,1,1,1,1,1,1,1,1,1,1,1,1,1,1,1,1,1,1,0,0,0,0,0,0,0,0,1,1,1,1,1,1,1,1,1,1,1,1,1,1,1,1,1,1,1,0,0,0,0,1,1,1,1,1,1,1,1,1,1,1,1,1,1,1,1,1,1,1,1,1,1,0,0,0,0,0,0,0,0,0,0,0,0,0,0,1,1,1,1,1,1,1,1,1,1,1,1,1,1,1,1,1,1,1,1,1,1,1,1,1,1,1,1,1,
		1,1,1,1,1,1,1,1,1,1,1,1,1,1,1,1,1,1,1,1,1,1,1,1,1,1,1,1,1,1,1,1,0,0,0,0,0,0,0,1,1,1,1,1,1,1,1,1,1,1,1,1,1,1,1,1,1,1,1,1,0,1,1,1,1,1,1,1,1,1,1,1,1,1,1,1,1,1,1,1,1,1,1,1,1,0,0,1,0,0,0,0,0,0,0,0,0,0,0,1,1,1,1,1,1,1,1,1,1,1,1,1,1,1,1,1,1,1,1,1,1,1,1,1,1,1,1,1,
		1,1,1,1,1,1,1,1,1,1,1,1,1,1,1,1,1,1,1,1,1,1,1,1,1,1,1,1,1,1,1,1,0,0,0,0,0,0,1,1,1,1,1,1,1,1,1,1,1,1,1,1,1,1,1,1,1,1,1,1,1,1,1,1,1,1,1,1,1,1,1,1,1,1,1,1,1,1,1,1,1,1,1,1,1,1,1,1,1,0,0,0,0,0,0,0,0,0,0,1,1,1,1,1,1,1,1,1,1,1,1,1,1,1,1,1,1,1,1,1,1,1,1,1,1,1,1,1,
		1,1,1,1,1,1,1,1,1,1,1,1,1,1,1,1,1,1,1,1,1,1,1,1,1,1,1,1,1,1,1,1,0,0,0,0,0,0,1,1,1,0,0,0,0,0,0,0,1,1,1,1,1,1,1,1,1,1,1,1,1,1,1,1,1,1,1,1,1,1,1,1,1,1,1,1,1,1,1,0,0,1,1,1,1,1,1,1,0,0,0,0,0,1,0,0,1,1,1,1,1,1,1,1,1,0,1,1,1,1,1,1,1,1,1,1,1,1,1,1,1,1,1,1,1,1,1,1,
		1,1,1,1,1,1,1,1,1,1,1,1,1,1,1,1,1,1,1,1,1,1,1,1,1,1,1,1,1,1,1,1,0,0,0,0,0,1,0,1,1,0,0,0,0,0,0,0,1,1,1,1,1,1,1,1,1,1,1,1,1,1,1,1,1,1,1,1,1,1,1,1,1,1,1,1,0,0,0,0,0,0,1,1,1,1,1,1,1,1,0,0,1,1,0,0,0,1,1,1,1,1,1,0,0,0,0,0,1,1,1,1,1,1,1,1,1,1,1,1,1,1,1,1,1,1,1,1,
		1,1,1,1,1,1,1,1,1,1,1,1,1,1,1,1,1,1,1,1,1,1,1,1,1,1,1,1,1,1,1,1,0,0,0,0,0,0,0,1,0,0,0,0,0,0,0,0,1,1,1,1,1,1,1,1,1,1,1,1,0,0,0,1,1,1,1,1,1,1,1,1,1,1,1,1,1,1,1,1,1,1,1,1,1,1,1,1,1,1,0,0,0,0,0,0,0,0,0,1,1,1,0,0,0,0,0,0,1,1,1,1,1,1,1,1,1,1,1,1,1,1,1,1,1,1,1,1,
		1,1,1,1,1,1,1,1,1,1,1,1,1,1,1,1,1,1,1,1,1,1,1,1,1,1,1,1,1,1,1,1,0,0,0,0,0,0,0,0,0,1,1,0,0,0,0,0,0,1,1,1,1,1,1,1,1,1,0,0,0,0,0,0,0,0,1,1,1,1,1,1,1,1,1,1,1,1,1,1,1,1,1,1,1,1,1,1,1,1,0,0,0,0,0,0,0,0,0,0,1,1,0,0,0,0,1,1,1,1,1,1,1,1,1,1,1,1,1,1,1,1,1,1,1,1,1,1,
		1,1,1,1,1,1,1,1,1,1,1,1,1,1,1,1,1,1,1,1,1,1,1,1,1,1,1,1,1,1,1,0,0,0,0,0,0,0,0,0,0,1,0,0,1,1,1,1,1,1,1,1,1,1,1,1,1,1,1,0,0,0,0,0,0,0,1,1,1,1,1,1,1,1,1,1,1,1,1,1,1,1,1,1,1,1,1,1,0,0,0,0,0,0,0,0,0,0,0,0,1,1,0,0,0,1,1,1,1,1,1,1,1,1,1,1,1,1,1,1,1,1,1,1,1,1,1,1,
		1,1,1,1,1,1,1,1,1,1,1,1,1,1,1,1,1,1,1,1,1,1,1,1,1,1,1,1,1,0,0,0,0,0,0,0,0,0,1,1,1,1,1,1,1,1,1,1,1,1,1,1,1,1,1,1,1,1,1,0,0,0,0,0,0,0,0,1,1,1,1,1,1,1,1,1,1,1,1,1,1,1,0,0,0,0,0,0,0,0,0,0,0,0,0,0,0,0,0,0,0,1,0,0,1,1,1,1,1,1,1,1,1,1,1,1,1,1,1,1,1,1,1,1,1,1,1,1,
		1,1,1,1,1,1,1,1,1,1,1,1,1,1,1,1,1,1,1,1,1,1,1,1,1,1,1,1,0,0,0,0,0,0,0,0,0,0,1,1,1,1,1,1,1,1,1,1,1,1,1,1,1,1,1,1,1,1,0,0,0,0,0,0,0,0,1,1,1,1,1,1,1,1,1,1,1,1,1,1,1,1,1,1,0,0,0,0,0,0,0,0,0,0,0,0,0,0,0,0,0,0,0,0,0,0,1,1,1,1,1,1,1,1,1,1,1,1,1,1,1,1,1,1,1,1,1,1,
		1,1,1,1,1,1,1,1,1,1,1,1,1,1,1,1,1,1,1,1,1,1,1,1,1,1,1,1,1,0,0,0,0,0,0,0,0,0,0,1,1,1,1,1,1,1,1,1,1,1,1,1,1,1,1,0,1,1,1,0,0,0,0,0,0,0,1,1,1,1,1,1,1,1,1,1,1,1,1,1,1,1,1,1,1,0,0,0,0,0,0,0,0,0,0,0,0,0,0,0,0,0,0,0,0,0,0,1,1,1,1,1,1,1,1,1,1,1,1,1,1,1,1,1,1,1,1,1,
		1,1,1,1,1,1,1,1,1,1,1,1,1,1,1,1,1,1,1,1,1,1,1,1,1,1,1,1,1,1,1,0,0,0,0,0,0,0,0,0,0,0,1,1,1,1,1,1,1,1,1,1,1,1,1,0,1,1,1,0,0,0,0,0,0,0,0,1,1,1,1,0,0,0,1,1,1,1,1,1,1,1,1,0,0,0,0,0,0,0,0,0,0,0,0,0,0,0,0,0,0,0,0,0,0,0,0,0,1,1,1,1,1,1,1,1,1,1,1,1,1,1,1,1,1,1,1,1,
		1,1,1,1,1,1,1,1,1,1,1,1,1,1,1,1,1,1,1,1,1,1,1,1,1,1,1,1,1,1,1,0,0,0,0,0,0,0,0,0,0,0,1,1,1,1,1,1,1,1,1,1,1,0,0,0,1,1,1,0,0,0,0,0,0,0,0,0,1,1,0,0,0,0,0,0,0,1,1,1,0,0,0,0,0,0,0,0,0,0,0,0,0,0,0,0,0,0,0,0,0,0,0,1,1,0,0,0,1,1,1,1,1,1,1,1,1,1,1,1,1,1,1,1,1,1,1,1,
		1,1,1,1,1,1,1,1,1,1,1,1,1,1,1,1,1,1,1,1,1,1,1,1,1,1,1,1,1,1,1,0,0,0,0,0,0,0,0,0,0,0,1,1,1,1,1,1,1,1,1,0,0,0,0,0,0,1,0,0,0,0,0,0,0,0,0,0,0,0,0,0,0,0,0,0,0,0,0,0,0,0,0,0,0,0,0,0,0,0,0,0,0,0,0,0,0,0,0,0,0,0,0,1,1,1,0,0,1,1,1,1,1,1,1,1,1,1,1,1,1,1,1,1,1,1,1,1,
		1,1,1,1,1,1,1,1,1,1,1,1,1,1,1,1,1,1,1,1,1,1,1,1,1,1,1,1,1,1,0,0,0,0,0,0,0,0,0,0,0,0,0,0,0,0,0,0,0,0,0,0,0,0,0,0,0,1,0,0,0,0,0,0,0,0,0,0,0,0,0,0,0,0,0,0,0,0,0,0,0,0,0,0,0,0,0,0,0,0,0,0,0,0,0,0,0,0,0,0,0,0,0,0,1,1,0,0,1,1,1,1,1,1,1,1,1,1,1,1,1,1,1,1,1,1,1,1,
		1,1,1,1,1,1,1,1,1,1,1,1,1,1,1,1,1,1,1,1,1,1,1,1,1,1,1,1,1,1,0,0,0,0,0,0,0,0,0,0,0,0,0,0,0,0,0,0,0,0,0,0,0,0,0,0,0,1,0,0,0,0,0,0,0,0,0,0,0,0,0,0,0,0,0,0,0,0,0,0,0,0,0,0,0,0,0,0,0,0,0,0,0,0,0,0,0,0,0,0,0,0,0,0,0,1,0,0,1,1,1,1,1,1,1,1,1,1,1,1,1,1,1,1,1,1,1,1,
		1,1,1,1,1,1,1,1,1,1,1,1,1,1,1,1,1,1,1,1,1,1,1,1,1,1,1,1,1,1,0,0,0,0,0,0,0,0,0,0,0,0,0,0,0,0,0,0,0,0,0,0,0,0,0,0,1,0,0,0,0,0,0,0,0,0,0,0,0,0,0,0,0,0,0,0,0,0,0,0,0,0,0,0,0,0,0,0,0,0,0,0,0,0,0,0,0,0,0,0,0,0,0,0,0,1,0,0,1,1,1,1,1,1,1,1,1,1,1,1,1,1,1,1,1,1,1,1,
		0,0,0,1,1,1,1,1,1,1,1,1,1,1,1,1,1,1,1,1,1,1,1,1,1,1,1,1,1,1,0,0,0,0,0,0,0,0,0,0,0,0,0,0,0,0,0,0,0,0,0,0,0,0,0,1,1,0,0,0,0,0,0,0,0,0,0,0,0,0,0,0,0,0,0,0,0,0,0,0,0,0,0,0,0,0,0,0,0,0,0,0,0,0,0,0,0,0,0,0,0,0,0,0,0,0,0,0,1,1,1,1,1,1,1,1,1,1,1,1,1,1,1,1,1,1,1,1,
		0,1,1,1,1,1,1,1,1,1,1,1,1,1,1,1,1,1,1,1,1,1,1,1,1,1,1,1,1,1,0,0,0,0,0,0,0,0,0,0,0,0,0,0,0,0,0,0,0,0,0,0,0,0,1,1,0,0,0,0,0,0,0,0,0,0,0,0,0,0,0,0,1,0,0,0,0,0,0,0,0,0,0,0,0,0,0,0,0,0,0,0,0,0,0,0,0,0,0,0,0,0,0,0,0,0,0,0,1,1,1,1,1,1,1,1,1,1,1,1,1,1,1,1,1,1,1,1,
		0,1,1,1,1,1,1,1,1,1,1,1,1,1,1,1,1,1,1,1,1,1,1,1,1,1,1,1,1,1,0,0,0,0,0,0,0,0,0,0,0,0,0,0,0,0,0,0,0,0,0,0,0,1,1,1,0,0,0,0,0,0,0,0,0,0,0,0,0,0,0,0,1,1,1,1,0,0,0,0,0,0,0,0,0,0,0,0,0,0,0,0,0,0,0,0,0,0,0,0,0,0,0,0,0,0,0,0,1,1,1,1,1,1,1,1,1,1,1,1,1,1,1,1,1,1,1,1,
		0,1,1,1,1,1,1,1,1,1,1,1,1,1,1,1,1,1,1,1,1,1,1,1,1,1,1,1,1,1,0,0,0,0,0,0,0,0,0,0,0,0,0,0,0,0,0,0,0,0,0,1,1,1,1,0,0,0,0,0,0,0,0,0,0,0,0,0,0,0,0,0,0,1,1,1,1,1,1,0,0,0,0,0,0,0,0,0,0,0,0,0,0,0,0,0,0,0,0,0,0,0,0,0,0,0,0,1,1,1,1,1,1,1,1,1,1,1,1,1,1,1,1,1,1,1,1,1,
		0,1,1,1,1,1,1,1,1,1,1,1,1,1,1,1,1,1,1,1,1,1,1,1,1,1,1,1,1,1,0,0,0,0,0,0,0,0,0,0,0,0,0,0,0,0,0,0,0,0,1,1,1,1,0,0,0,0,0,0,0,0,0,0,0,0,0,0,0,0,0,0,0,1,1,1,1,1,1,0,0,0,0,0,0,0,0,0,0,0,0,0,0,0,0,0,0,0,0,0,0,0,0,0,0,0,0,1,1,1,1,1,1,1,1,1,1,1,1,1,1,1,1,1,1,1,1,1,
		0,1,1,1,1,1,1,1,1,1,1,1,1,1,1,1,1,1,1,1,1,1,1,1,1,1,1,1,1,1,1,0,0,0,0,0,0,0,0,0,0,0,0,0,0,0,1,1,1,1,1,1,1,1,0,0,0,0,0,0,0,0,0,0,0,0,0,0,0,0,0,0,0,1,1,1,1,1,1,0,0,0,0,0,0,0,0,0,0,0,0,0,0,0,0,0,0,0,0,0,0,0,0,0,0,0,0,1,1,1,1,1,1,1,1,1,1,1,1,1,1,1,1,1,1,1,1,1,
		0,1,1,1,1,1,1,1,1,1,1,1,1,1,1,1,1,1,1,1,1,1,1,1,1,1,1,1,1,1,1,0,0,0,0,0,0,0,0,0,0,0,0,0,0,0,0,1,1,1,1,1,1,1,0,0,0,0,0,0,0,0,0,0,0,0,0,0,0,0,0,0,0,1,1,1,1,1,1,1,0,0,0,0,0,0,0,0,0,0,0,0,0,0,0,0,0,0,0,0,0,0,0,0,0,0,1,1,1,1,1,1,1,1,1,1,1,1,1,1,1,1,1,1,1,1,1,1,
		0,1,1,1,1,1,1,1,1,1,1,1,1,1,1,1,1,1,1,1,1,1,1,1,1,1,1,1,1,1,1,1,0,0,0,0,0,0,0,0,0,0,0,0,0,0,0,1,1,1,1,1,1,1,0,0,0,0,0,0,0,0,0,0,0,0,1,1,0,0,0,1,1,1,1,1,1,1,1,1,1,0,0,0,0,0,0,0,0,0,0,0,0,0,0,0,0,0,0,0,0,0,0,0,0,0,1,1,1,1,1,1,1,1,1,1,1,1,1,1,1,1,1,1,1,1,1,1,
		0,0,1,1,1,1,1,1,1,1,1,1,1,1,1,1,1,1,1,1,1,1,1,1,1,1,1,1,1,1,1,1,0,0,0,0,0,0,0,0,0,0,0,0,0,0,0,1,1,1,1,1,1,1,1,0,0,0,1,0,0,0,0,0,1,1,1,1,1,1,1,1,1,1,1,1,1,1,1,1,1,1,1,0,0,0,0,0,0,0,0,0,0,0,0,0,0,0,0,0,0,0,0,0,0,1,1,1,1,1,1,1,1,1,1,1,1,1,1,1,1,1,1,1,1,1,1,1,
		0,0,1,1,1,1,1,1,1,1,1,1,1,1,1,1,1,1,1,1,1,1,1,1,1,1,1,1,1,1,1,1,0,0,0,0,0,0,0,0,0,0,0,0,0,0,1,1,1,1,1,1,1,1,1,1,1,1,1,1,1,0,1,1,1,1,1,1,1,1,1,1,1,1,1,1,1,1,1,1,1,1,1,1,1,1,1,1,1,1,0,0,0,0,0,0,0,0,0,0,0,0,0,0,1,1,1,1,1,1,1,1,1,1,1,1,1,1,1,1,1,1,1,1,1,1,1,1,
		0,0,1,1,1,1,1,1,1,1,1,1,1,1,1,1,1,1,1,1,1,1,1,1,1,1,1,1,1,1,1,1,0,0,0,0,0,0,0,0,0,0,0,0,0,0,1,1,1,1,1,1,0,0,0,0,1,1,1,1,1,1,1,1,1,1,1,1,1,1,1,0,0,0,0,0,1,1,1,1,1,1,1,1,1,1,1,1,1,1,0,0,0,0,0,0,0,0,0,0,1,1,1,1,1,1,1,1,1,1,1,1,1,1,1,1,1,1,1,1,1,1,1,1,1,1,1,1,
		0,1,1,1,1,1,1,1,1,1,1,1,1,1,1,1,1,1,1,1,1,1,1,1,1,1,1,1,1,1,1,1,1,0,0,0,0,0,0,0,0,0,0,0,0,1,1,1,1,1,1,0,0,0,0,0,1,1,1,1,1,1,1,1,1,1,1,1,1,1,1,0,0,0,0,0,1,1,1,1,1,1,1,1,1,1,1,1,1,1,1,1,1,0,0,0,0,0,0,0,1,1,1,1,1,1,1,1,1,1,1,1,1,1,1,1,1,1,1,1,1,1,1,1,1,1,1,1,
		0,1,1,1,1,1,1,1,1,1,1,1,1,1,1,1,1,1,1,1,1,1,1,1,1,1,1,1,1,1,1,1,1,0,0,0,0,0,0,0,0,0,0,0,0,1,1,1,1,1,0,0,0,0,0,0,0,1,1,1,1,1,1,1,1,1,1,1,1,0,0,0,0,0,0,0,1,1,1,1,1,1,1,1,1,1,1,1,1,1,1,1,1,0,0,0,0,0,0,0,1,1,1,1,1,1,1,1,1,1,1,1,1,1,1,1,1,1,1,1,1,1,1,1,1,1,1,1,
		0,1,1,1,1,1,1,1,1,1,1,1,1,1,1,1,1,1,1,1,1,1,1,1,1,1,1,1,1,1,1,1,1,1,0,0,0,0,0,0,0,0,0,0,1,1,1,1,1,1,0,0,0,0,0,0,0,0,1,1,1,1,1,1,1,1,1,0,0,0,0,0,0,0,0,0,1,1,1,1,1,1,1,1,1,1,1,1,1,1,1,1,1,0,0,0,0,0,0,1,1,1,1,1,1,1,1,1,1,1,1,1,1,1,1,1,1,1,1,1,1,1,1,1,1,1,1,1,
		0,1,1,1,1,1,1,1,1,1,1,1,1,1,1,1,1,1,1,1,1,1,1,1,1,1,1,1,1,1,1,1,1,1,0,0,0,0,0,0,0,1,0,1,1,1,1,1,1,1,0,0,0,0,0,0,0,0,0,0,0,1,1,1,1,1,0,0,0,0,0,0,0,0,0,0,1,1,1,1,1,1,1,1,1,1,1,1,1,1,1,1,1,0,0,0,0,0,0,1,1,1,1,1,1,1,1,1,1,1,1,1,1,1,1,1,1,1,1,1,1,1,1,1,1,1,1,1,
		0,1,1,1,1,1,1,1,1,1,1,1,1,1,1,1,1,1,1,1,1,1,1,1,1,1,1,1,1,1,1,1,1,1,1,0,0,0,0,0,0,1,0,1,1,1,1,1,1,1,1,1,0,0,0,0,0,0,0,0,0,0,0,0,0,0,0,0,0,0,0,0,0,0,0,0,1,1,1,1,1,1,1,1,1,1,1,1,1,1,1,1,1,1,0,0,0,0,0,1,1,1,1,1,1,1,1,1,1,1,1,1,1,1,1,1,1,1,1,1,1,1,1,1,1,1,1,1,
		0,1,1,1,1,1,1,1,1,1,1,1,1,1,1,1,1,1,1,1,1,1,1,1,1,1,1,1,1,1,1,1,1,1,1,0,0,0,0,0,0,0,0,1,1,1,1,1,1,1,1,1,0,0,0,0,0,0,0,1,1,1,1,1,1,1,1,1,1,1,1,1,1,1,1,1,1,1,1,1,1,1,1,1,1,1,1,1,1,1,1,1,1,1,0,0,0,0,1,1,1,1,1,1,0,0,0,0,0,0,0,0,0,0,0,0,0,0,0,0,0,0,0,0,0,0,0,0,
		0,1,1,1,1,1,1,1,1,1,1,1,1,1,1,1,1,1,1,1,1,1,1,1,1,1,1,1,1,1,1,1,1,1,1,0,0,0,0,0,0,0,0,1,1,1,1,1,1,1,1,1,0,0,0,0,0,1,1,1,1,1,1,1,1,1,1,1,1,1,1,1,1,1,1,1,1,1,1,1,1,1,1,1,1,1,1,1,1,1,1,1,0,0,0,0,0,0,0,1,0,0,0,0,0,0,0,0,0,0,0,0,0,0,0,0,0,0,0,0,0,0,0,0,0,0,0,0,
		0,0,1,1,1,1,1,1,1,1,1,1,1,1,1,1,1,1,1,1,1,1,1,1,1,1,1,1,1,1,1,1,1,1,1,1,0,0,0,0,0,0,0,0,1,1,1,1,1,1,1,1,1,1,1,1,1,1,1,1,1,1,1,1,1,1,1,1,1,1,1,1,1,1,1,1,1,1,1,1,1,1,1,1,1,1,1,1,1,1,1,1,1,0,0,0,0,0,0,0,0,0,0,0,0,0,0,0,0,0,0,0,0,0,0,0,0,0,0,0,0,0,0,0,0,0,0,0,
		0,0,1,1,1,1,1,1,1,1,1,1,1,1,1,1,1,1,1,1,1,1,1,1,1,1,1,1,1,1,1,1,1,1,1,1,0,0,0,0,0,0,0,0,0,1,1,1,1,1,1,1,1,1,1,1,1,1,1,1,1,1,1,1,1,1,1,1,1,1,1,1,1,1,1,1,1,1,1,1,1,1,1,1,1,1,1,1,1,1,1,1,1,0,0,0,0,0,0,0,0,0,0,0,0,0,0,0,0,0,0,0,0,0,0,0,0,0,0,0,0,0,0,0,0,0,0,0,
		0,0,1,1,1,1,1,1,1,1,1,1,1,1,1,1,1,1,1,1,1,1,1,1,1,1,1,1,1,1,1,1,1,1,1,1,0,0,0,0,0,0,0,0,0,0,1,1,1,1,1,1,1,1,1,1,1,1,1,0,0,0,0,0,1,0,0,0,0,0,0,0,0,0,1,1,1,1,1,1,1,1,1,1,1,1,1,1,1,1,1,1,1,1,0,0,0,0,0,0,0,0,0,0,0,0,0,0,0,0,0,0,0,0,0,0,0,0,0,0,0,0,0,0,0,0,0,0,
		0,0,1,1,1,1,1,1,1,1,1,1,1,1,1,1,1,1,1,1,1,1,1,1,1,1,1,1,1,1,1,1,1,1,1,1,1,0,0,0,0,0,0,0,0,0,1,1,1,1,1,1,1,1,1,1,0,0,0,0,0,0,0,0,0,0,0,0,0,0,0,0,0,0,1,1,1,1,1,1,1,1,1,1,1,1,1,1,1,1,1,1,1,1,0,0,0,0,0,0,0,0,0,0,0,0,0,0,0,0,0,0,0,0,0,0,0,0,0,0,0,0,0,0,0,0,0,0,
		0,0,1,1,1,1,1,1,1,1,1,1,1,1,1,1,1,1,1,1,1,1,1,1,1,1,1,1,1,1,1,1,1,1,1,1,1,0,0,0,0,0,0,0,0,0,1,1,1,1,1,1,1,1,1,1,0,0,0,0,0,0,0,0,0,0,0,0,0,0,0,0,1,1,1,1,1,1,1,1,1,1,1,1,1,1,1,1,1,1,1,1,1,1,1,0,0,0,0,0,0,0,0,0,0,0,0,0,0,0,0,0,0,0,0,0,1,0,0,0,0,0,0,0,0,0,0,0,
		0,0,1,1,1,1,1,1,1,1,1,1,1,1,1,0,1,1,1,1,1,1,1,1,1,1,1,1,1,1,1,1,1,1,1,1,1,1,0,0,0,0,0,0,0,1,1,1,1,1,1,1,0,1,1,1,1,1,1,0,0,0,0,0,0,0,0,0,0,1,0,1,0,0,0,0,0,0,1,1,1,1,1,1,1,1,1,1,1,1,1,1,1,1,1,0,0,0,0,0,0,0,1,1,1,1,1,1,1,1,1,1,1,1,1,1,1,1,1,1,1,1,1,1,1,1,1,1,
		0,0,1,1,1,1,1,1,1,1,1,1,1,1,1,0,0,1,1,1,1,1,1,1,1,1,1,1,1,1,1,1,1,1,1,1,1,1,0,0,0,0,0,0,0,1,1,1,1,1,1,0,0,0,0,0,0,1,1,1,1,0,0,0,1,1,0,0,0,0,0,0,0,0,0,0,0,0,0,0,1,1,1,1,1,1,1,1,1,1,1,1,1,1,1,0,0,0,0,0,0,1,1,1,1,1,1,1,1,1,1,1,1,1,1,1,1,1,1,1,1,1,1,1,1,1,1,1,
		0,0,1,1,1,1,1,1,1,1,1,1,1,1,1,0,0,1,0,1,1,1,1,1,1,1,1,1,1,1,1,1,1,1,1,1,1,1,1,0,0,0,0,0,0,1,1,1,1,1,1,0,0,0,0,0,0,0,0,0,0,0,0,0,0,0,0,0,0,0,0,0,0,0,0,0,0,0,0,0,0,1,1,1,1,1,1,1,1,1,1,1,1,1,1,0,0,0,0,0,1,1,1,1,1,1,1,1,1,1,1,1,1,1,1,1,1,1,1,1,1,1,1,1,1,1,1,1,
		0,0,1,1,1,1,1,1,1,1,1,1,1,1,1,1,1,1,1,1,1,1,1,1,1,1,1,1,1,1,1,1,1,1,1,1,1,1,1,0,0,0,0,0,0,1,1,1,1,1,0,0,0,0,0,0,0,0,0,0,0,0,0,0,0,0,0,0,0,0,0,0,0,0,0,0,0,0,0,0,0,1,1,1,1,1,1,1,1,1,1,1,1,1,0,0,0,0,0,1,1,1,1,1,1,1,1,1,1,1,1,1,1,1,1,1,1,1,1,1,1,1,1,1,1,1,1,1,
		0,0,1,1,1,1,1,1,1,1,1,1,1,1,1,1,1,1,1,1,1,1,1,1,1,1,1,1,1,1,1,1,1,1,1,1,1,1,1,1,0,0,0,0,1,1,1,1,1,0,0,0,0,0,0,0,0,0,0,0,0,0,0,0,0,0,0,0,0,0,0,0,0,0,0,0,0,0,0,0,0,0,1,1,1,1,1,1,1,1,1,1,1,1,0,0,0,0,1,1,1,1,1,1,1,1,1,1,1,1,1,1,1,1,1,1,1,1,1,1,1,1,1,1,1,1,1,1,
		0,0,1,1,1,1,1,1,1,1,1,1,1,1,1,1,1,1,1,1,1,1,1,1,1,1,1,1,1,1,1,1,1,1,1,1,1,1,1,1,0,0,0,0,1,1,1,1,1,0,0,0,0,0,0,0,0,0,0,0,0,1,1,1,1,1,1,1,1,1,1,1,1,0,0,0,0,0,0,0,0,0,1,1,1,1,1,1,1,1,1,1,1,1,0,0,0,0,1,1,1,1,1,1,1,1,1,1,1,1,1,1,1,1,1,1,1,1,1,1,1,1,1,1,1,1,1,1,
		0,1,1,1,1,1,1,1,1,1,1,1,1,1,1,1,1,1,1,1,1,1,1,1,1,1,1,1,1,1,1,1,1,1,1,1,1,1,1,1,1,0,0,1,1,1,1,1,1,0,0,0,0,0,0,0,0,0,0,0,1,1,1,1,1,1,1,1,1,1,1,1,1,0,0,0,0,0,0,0,0,1,1,1,1,1,1,1,1,1,1,1,1,1,0,0,0,1,1,1,1,1,1,1,1,1,1,1,1,1,1,1,1,1,1,1,1,1,1,1,1,1,1,1,1,1,1,1,
		0,0,1,1,1,1,1,1,1,1,1,1,1,1,1,1,1,1,1,1,1,1,1,1,1,1,1,1,1,1,1,1,1,1,1,1,1,1,1,1,1,1,0,1,1,1,1,1,1,0,0,0,0,0,0,0,0,0,0,1,1,1,1,1,1,1,1,1,1,1,1,1,1,0,0,0,0,0,0,0,0,1,1,1,1,1,1,1,1,1,1,1,1,0,0,0,0,1,1,1,1,1,1,1,1,1,1,1,1,1,1,1,1,1,1,1,1,1,1,1,1,1,1,1,1,1,1,1,
		0,0,1,1,1,1,1,1,1,1,1,1,1,1,1,1,1,1,1,1,1,1,1,1,1,1,1,1,1,1,1,1,1,1,1,1,1,1,1,1,1,1,0,0,1,1,1,1,1,1,0,0,0,0,0,0,0,0,0,0,1,1,1,1,1,1,1,1,1,1,1,1,1,0,0,0,0,0,0,0,0,0,0,1,1,1,1,1,1,1,1,1,0,0,0,0,0,1,1,1,1,1,1,1,1,1,1,1,1,1,1,1,1,1,1,1,1,1,1,1,1,1,1,1,1,1,1,1,
		0,0,1,1,1,1,1,1,1,1,1,1,1,1,1,1,1,1,1,1,1,1,1,1,1,1,1,1,1,1,1,1,1,1,1,1,1,1,1,1,1,1,1,0,0,1,1,1,1,1,0,0,0,0,0,0,0,0,0,0,1,1,1,1,1,1,1,1,1,1,1,1,1,0,0,0,0,0,0,0,0,0,0,1,1,1,1,1,1,1,1,0,0,0,0,0,0,1,1,1,1,1,1,1,1,1,1,1,1,1,1,1,1,1,1,1,1,1,1,1,1,1,1,1,1,1,1,1,
		0,0,1,1,1,1,1,1,1,1,1,1,1,1,1,1,1,1,1,1,1,1,1,1,1,1,1,1,1,1,1,1,1,1,1,1,1,1,1,1,1,1,1,1,0,1,1,1,1,1,0,0,0,0,0,0,0,0,0,0,0,0,0,0,0,1,0,0,0,0,0,0,0,0,0,0,0,0,0,0,0,0,1,1,1,1,1,1,1,1,1,0,0,0,0,0,0,1,1,1,1,1,1,1,1,1,1,1,1,1,1,1,1,1,1,1,1,1,1,1,1,1,1,1,1,1,1,1,
		1,1,1,1,1,1,1,1,1,1,1,1,1,1,1,1,1,1,1,1,1,1,1,1,1,1,1,1,1,1,1,1,1,1,1,1,1,1,1,1,1,1,1,1,1,0,1,1,1,1,0,0,0,0,0,0,0,0,0,0,0,0,0,0,0,0,0,0,0,0,0,0,0,0,0,0,0,0,0,0,0,0,1,1,1,1,1,1,1,1,0,0,0,0,0,0,0,1,1,1,1,1,1,1,1,1,1,1,1,1,1,1,1,1,1,1,1,1,1,1,1,1,1,1,1,1,1,1,
		0,0,1,1,1,1,1,1,1,1,1,1,1,1,1,1,1,1,1,1,1,1,1,1,1,1,1,1,1,1,1,1,1,1,1,1,1,1,1,1,1,1,1,1,1,1,1,1,1,1,0,0,0,0,0,0,0,0,0,0,0,0,0,0,0,0,0,0,0,0,0,0,0,0,0,0,0,0,0,0,0,1,1,1,1,1,1,1,1,0,0,0,0,0,0,0,0,1,1,1,1,1,1,1,1,1,1,1,1,1,1,1,1,1,1,1,1,1,1,1,1,1,1,1,1,1,1,1,
		1,0,1,1,1,1,1,1,1,1,1,1,1,1,1,1,1,1,1,1,1,1,1,1,1,1,1,1,1,1,1,1,1,1,1,1,1,1,1,1,1,1,1,1,1,1,0,0,1,1,0,0,0,0,0,0,0,0,0,0,0,0,0,0,0,0,0,0,0,0,0,0,0,0,0,0,0,0,0,0,0,1,1,1,1,1,1,1,0,0,0,0,0,0,0,0,0,0,1,1,1,1,1,1,1,1,1,1,1,1,1,1,1,1,1,1,1,1,1,1,1,1,1,1,1,1,1,1,
		1,1,1,1,1,1,1,1,1,1,1,1,1,1,1,1,1,1,1,1,1,1,1,1,1,1,1,1,1,1,1,1,1,1,1,1,1,1,1,1,1,1,1,1,1,1,0,0,0,1,0,0,0,0,0,0,0,0,0,0,0,0,0,0,0,0,0,0,0,0,0,0,0,0,0,0,0,0,0,0,1,1,1,1,1,1,1,0,0,1,0,0,0,0,0,0,0,0,0,0,0,1,1,0,0,0,0,0,0,0,0,0,1,1,1,1,1,1,1,1,1,1,1,1,1,1,1,1,
		1,1,1,1,1,1,1,1,1,1,1,1,1,1,1,1,1,1,1,1,1,1,1,1,1,1,1,1,1,1,1,1,1,1,1,1,1,1,1,1,1,1,1,1,1,1,0,0,0,0,1,0,1,0,0,0,0,0,0,0,0,0,0,0,0,0,0,0,0,0,0,0,0,0,0,0,1,1,1,1,1,1,1,1,1,1,1,1,1,1,0,0,0,0,0,0,0,0,0,0,0,0,0,0,0,0,0,0,0,0,0,0,0,0,0,1,1,1,1,1,1,1,1,1,1,1,1,1,
		1,1,1,1,1,1,1,1,1,1,1,1,1,1,1,1,1,1,1,1,1,1,1,1,1,1,1,1,1,1,1,1,1,1,1,1,1,1,1,1,1,1,1,1,1,1,0,0,0,0,0,1,1,1,0,0,0,0,0,0,0,0,0,0,0,0,0,0,0,0,0,0,0,0,1,1,1,1,1,1,1,1,1,1,1,1,1,1,1,1,0,0,0,0,0,0,0,0,0,0,0,0,0,0,0,0,0,0,0,0,0,0,0,0,0,0,0,0,1,1,1,1,1,1,1,1,1,1,
		1,1,1,1,1,1,1,1,1,1,1,1,1,1,1,1,1,1,1,1,1,1,1,1,1,1,1,1,1,1,1,1,1,1,1,1,1,1,1,1,1,1,1,1,1,1,0,0,0,0,0,1,1,1,1,1,0,0,0,0,0,0,0,0,0,0,1,1,1,1,1,1,1,1,1,1,1,1,1,1,1,1,1,1,1,1,1,1,1,1,0,0,0,0,0,0,0,0,0,0,0,0,0,0,0,0,0,0,0,0,0,0,0,0,0,0,0,0,0,0,1,0,0,0,1,1,1,1,
		1,1,1,1,1,1,1,1,1,1,1,1,1,1,1,1,1,1,1,1,1,1,1,1,1,1,1,1,1,1,1,1,1,1,1,1,1,1,1,1,1,1,1,1,1,1,0,0,0,0,0,1,1,1,1,1,1,1,1,1,1,1,1,1,1,1,1,1,1,1,1,1,1,1,1,1,1,1,1,1,1,1,1,1,1,1,1,1,1,0,0,0,0,0,0,0,0,0,0,0,0,0,0,0,0,0,0,0,0,0,0,0,0,0,0,0,0,0,0,0,0,0,0,0,0,0,0,0,
		1,1,1,1,1,1,1,1,1,1,1,1,1,1,1,1,1,1,1,1,1,1,1,1,1,1,1,1,1,1,1,1,1,1,1,1,1,1,1,1,0,0,0,0,0,0,0,0,0,0,0,0,1,1,1,1,1,1,1,1,1,1,1,1,1,1,1,1,1,1,1,1,1,1,1,1,1,1,1,1,1,1,1,1,1,1,1,1,1,0,0,0,0,0,0,0,0,0,0,0,0,0,0,0,0,0,0,0,0,0,0,0,0,0,0,0,0,0,0,0,0,0,0,0,0,0,0,0,
		1,1,1,1,1,1,1,1,1,1,1,1,1,1,1,1,1,1,1,1,1,1,1,1,1,1,1,1,1,1,1,1,1,1,1,1,1,0,0,0,0,0,0,0,0,0,0,0,0,0,0,0,1,1,1,1,1,1,1,1,1,1,1,1,1,1,1,1,1,1,1,1,1,1,1,1,1,1,1,1,1,1,1,1,1,1,1,1,1,0,0,0,0,0,0,0,0,0,0,0,0,0,0,0,0,0,0,0,0,0,0,0,0,0,0,0,0,0,0,0,0,0,0,0,0,0,0,0,
		1,1,1,1,1,1,1,1,1,1,1,1,1,1,1,1,1,1,1,1,1,1,1,1,1,1,1,1,1,1,1,1,0,0,0,0,0,0,0,0,0,0,0,0,0,0,0,0,0,0,0,0,0,1,1,1,1,1,1,1,1,1,1,1,1,1,1,1,1,1,1,1,1,1,1,1,1,1,1,1,1,1,1,1,1,1,1,1,0,0,0,0,0,0,0,0,0,0,0,0,0,0,0,0,0,0,0,0,0,0,0,0,0,0,0,0,0,0,0,0,0,0,0,0,0,0,0,0,
		1,1,1,1,1,1,1,1,1,1,1,1,1,0,0,1,0,1,1,1,1,1,1,1,1,1,1,1,1,1,1,0,0,0,0,0,0,0,0,0,0,0,0,0,0,0,0,0,0,0,0,0,0,0,1,1,1,1,1,1,1,1,1,1,1,1,1,1,1,1,1,1,1,1,1,1,1,1,1,1,1,1,1,1,1,1,1,0,0,0,0,0,0,0,0,0,0,0,0,0,0,0,0,0,0,0,0,0,0,0,0,0,0,0,0,0,0,0,0,0,0,0,0,0,0,0,0,0,
		1,1,1,1,1,1,1,1,1,1,1,0,0,0,0,1,0,1,1,1,1,1,1,1,1,1,1,1,1,1,1,0,0,0,0,0,0,0,0,0,0,0,0,0,0,0,0,0,0,0,0,0,0,0,0,0,1,1,1,1,1,1,1,1,1,1,1,1,1,1,1,1,1,1,1,1,1,1,1,1,1,1,1,1,1,1,0,0,0,0,0,0,0,0,0,0,0,0,0,0,0,0,0,0,0,0,0,0,0,0,0,0,0,0,0,0,0,0,0,0,0,0,0,0,0,0,0,0,
		1,1,1,1,1,1,1,1,1,1,1,0,0,0,0,0,1,1,1,1,1,1,1,1,1,1,1,1,1,1,1,0,0,0,0,0,0,0,0,0,0,0,0,1,0,0,0,0,0,0,0,0,0,0,0,0,0,1,1,1,1,1,1,1,1,1,1,1,1,1,1,1,1,1,1,1,1,1,1,1,1,1,1,1,1,0,0,0,0,0,0,0,0,0,0,0,0,0,0,0,0,0,0,0,0,0,0,0,0,0,0,0,0,0,0,0,0,0,0,0,0,0,0,0,0,0,0,0,
		1,1,1,1,1,1,1,1,1,1,0,0,0,0,0,0,1,1,1,1,1,1,1,1,1,1,1,1,1,1,0,0,0,0,0,0,0,0,0,0,0,0,0,0,0,0,0,0,0,0,0,0,0,0,0,0,0,0,1,1,1,1,1,1,1,1,1,1,1,1,1,1,1,1,1,1,1,1,1,1,1,1,1,0,0,0,0,0,0,0,0,0,0,0,0,0,0,0,0,0,0,0,0,0,0,0,0,0,0,0,0,0,0,0,0,0,0,0,0,0,0,0,0,0,0,0,0,0,
		1,1,1,1,1,1,1,0,0,0,0,0,0,0,0,0,0,1,1,0,0,0,0,1,1,1,1,1,0,0,0,0,0,0,0,0,0,1,0,0,0,0,1,0,0,0,0,0,0,0,0,0,0,0,0,0,0,0,1,1,1,1,1,1,1,1,1,1,1,1,1,1,1,1,1,1,1,1,1,1,1,1,0,0,0,0,0,0,0,0,0,0,0,0,0,0,0,0,0,0,0,0,0,0,0,0,0,0,0,0,0,0,0,0,0,0,0,0,0,0,0,0,0,0,0,0,0,0,
		1,1,1,1,1,1,1,0,0,0,0,0,0,0,0,0,0,0,0,0,0,0,0,0,0,0,1,1,0,0,0,0,0,0,0,0,1,1,1,1,1,1,1,0,0,0,0,0,0,0,0,0,0,0,0,0,0,0,0,1,0,0,0,1,1,1,1,1,1,1,1,1,1,1,1,1,1,1,1,1,1,0,0,0,0,0,0,0,0,0,0,0,0,0,0,0,0,0,0,0,0,0,0,0,0,0,0,0,0,0,0,0,0,0,0,0,0,0,0,0,0,0,0,0,0,0,0,0,
		1,1,1,1,1,0,0,0,0,0,0,0,0,0,0,0,0,0,0,0,0,0,0,0,0,0,1,0,0,0,0,0,0,0,1,1,0,0,0,0,0,0,0,0,0,0,0,0,0,0,0,0,0,0,0,0,0,0,0,0,0,0,0,1,1,1,1,1,1,1,1,1,1,1,1,1,1,1,1,1,1,0,0,0,0,0,0,0,0,0,0,0,0,0,0,0,0,0,0,0,0,0,0,0,0,0,0,0,0,0,0,0,0,0,0,0,0,0,0,0,0,0,0,0,0,0,0,0,
		1,1,1,1,1,1,0,0,0,0,0,0,0,0,0,0,0,0,0,0,0,0,0,0,0,0,1,0,0,0,0,0,0,1,1,0,0,0,0,0,0,0,0,0,0,0,0,0,0,0,0,0,0,0,0,0,0,0,0,0,0,0,0,0,1,1,1,1,1,1,1,1,1,1,1,1,1,1,1,1,1,0,0,0,0,0,0,0,0,0,0,0,0,0,0,0,0,0,0,0,0,0,0,0,0,0,0,0,0,0,0,0,0,0,0,0,0,0,0,0,0,0,0,0,0,0,0,0,
		1,1,1,1,1,1,0,0,0,0,0,0,0,0,0,0,0,0,0,0,0,0,0,0,0,0,1,0,0,0,0,0,0,0,0,0,0,0,0,0,0,0,0,0,0,0,0,0,0,0,0,0,0,0,0,0,0,0,0,0,0,0,0,0,0,1,1,1,1,1,1,1,1,1,1,1,1,1,1,1,0,0,0,0,0,0,0,0,0,0,0,0,0,0,0,0,0,0,0,0,0,0,0,0,0,0,0,0,0,0,0,0,0,0,0,0,0,0,0,0,0,0,0,0,0,0,0,0,
		1,1,1,1,1,1,0,0,0,0,0,0,0,0,0,0,0,0,0,0,0,0,0,0,0,0,1,0,0,0,0,0,0,0,0,0,0,0,0,0,0,0,0,0,0,0,0,0,0,0,0,0,0,0,0,0,0,0,0,0,0,0,0,0,0,1,1,1,1,1,1,1,1,1,1,1,1,1,1,0,0,0,0,0,0,0,0,0,0,0,0,0,0,0,0,0,0,0,0,0,0,0,0,0,0,0,0,0,0,0,0,0,0,0,0,0,0,0,0,0,0,0,0,0,0,0,0,0,
		1,1,1,1,1,0,0,0,0,0,0,0,0,0,0,0,0,0,0,0,0,0,0,0,0,0,1,0,0,0,0,0,0,0,0,0,0,0,0,0,0,0,0,0,0,0,0,0,0,0,0,0,0,0,0,0,0,0,0,0,0,0,0,0,0,1,1,1,1,1,1,1,1,1,1,1,1,1,1,0,0,0,0,0,0,0,0,0,0,0,0,0,0,0,0,0,0,0,0,0,0,0,0,0,0,0,0,0,0,0,0,0,0,0,0,0,0,0,0,0,0,0,0,0,0,0,0,0,
		1,1,1,1,1,0,0,0,0,0,0,0,0,0,0,0,0,0,0,0,0,0,0,0,0,0,0,0,0,0,0,0,0,0,0,0,0,0,0,0,0,0,0,0,0,0,0,0,0,0,0,0,0,0,0,0,0,0,0,0,0,0,0,0,0,0,1,1,1,1,1,1,1,1,1,1,1,1,1,0,0,0,0,0,0,0,0,0,0,0,0,0,0,0,0,0,0,0,0,0,0,0,0,0,0,0,0,0,0,0,0,0,0,0,0,0,0,0,0,0,0,0,0,0,0,0,0,0,
		1,1,1,1,1,0,0,0,0,0,0,0,0,0,0,0,0,0,0,0,0,0,0,0,0,0,0,0,0,0,0,0,0,0,0,0,0,0,0,0,0,0,0,0,0,0,0,0,0,0,0,0,0,0,0,0,0,0,0,0,0,0,0,0,0,0,1,1,1,1,1,1,1,1,1,1,1,1,1,0,0,0,0,0,0,0,0,0,0,0,0,0,0,0,0,0,0,0,0,0,0,0,0,0,0,0,0,0,0,0,0,0,0,0,0,0,0,0,0,0,0,0,0,0,0,0,0,0,
		1,1,1,1,0,0,0,0,0,0,0,0,0,0,0,0,0,0,0,0,0,0,0,0,0,0,0,0,0,0,0,0,0,0,0,0,0,0,0,0,0,0,0,0,0,0,0,0,0,0,0,0,0,0,0,0,0,0,0,0,0,0,0,0,0,1,1,1,1,1,1,1,1,1,1,1,1,1,1,0,0,0,0,0,0,0,0,0,0,0,0,0,0,0,0,0,0,0,0,0,0,0,0,0,0,0,0,0,0,0,0,0,0,0,0,0,0,0,0,0,0,0,0,0,0,0,0,0,
		1,1,1,0,0,0,0,0,0,0,0,0,0,0,0,0,0,0,0,0,0,0,0,0,0,0,0,0,0,0,0,0,0,0,0,0,0,0,0,0,0,0,0,0,0,0,0,0,0,0,0,0,0,0,0,0,0,0,0,0,0,0,0,0,0,1,1,1,1,1,1,1,1,1,1,1,1,1,0,0,0,0,0,0,0,0,0,0,0,0,0,0,0,0,0,0,0,0,0,0,0,0,0,0,0,0,0,0,0,0,0,0,0,0,0,0,0,0,0,0,0,0,0,0,0,0,0,0,
		1,1,1,0,0,0,0,0,0,0,0,0,0,0,0,0,0,0,0,0,0,0,0,0,0,0,0,0,0,0,0,0,0,0,0,0,0,0,0,0,0,0,0,0,0,0,0,0,0,0,0,0,0,0,0,0,0,0,0,0,0,0,0,0,0,1,1,1,1,1,1,1,1,1,1,1,1,1,0,0,0,0,0,0,0,0,0,0,0,0,0,0,0,0,0,0,0,0,0,0,0,0,0,0,0,0,0,0,0,0,0,0,0,0,0,0,0,0,0,0,0,0,0,0,0,0,0,0,
		1,1,1,0,1,0,0,1,0,0,0,0,0,0,0,0,0,0,0,0,0,0,0,0,0,0,0,0,0,0,0,0,0,0,0,0,0,0,0,0,0,0,0,0,0,0,0,0,0,0,0,0,0,0,0,0,0,0,0,0,0,0,0,0,0,1,1,1,1,1,1,1,1,1,1,1,1,1,0,0,0,0,0,0,0,0,0,0,0,0,0,0,0,0,0,0,0,0,0,0,0,0,0,0,0,0,0,0,0,0,0,0,0,0,0,0,0,0,0,0,0,0,0,0,0,0,0,0,
		1,1,1,0,1,1,0,1,0,0,0,0,0,0,0,0,0,0,0,0,0,0,0,0,0,0,0,0,0,0,0,0,0,0,0,0,0,0,0,0,0,0,0,0,0,0,0,0,0,0,0,0,0,0,0,0,0,0,0,0,0,0,0,0,0,0,1,1,1,1,1,1,1,1,1,1,1,0,0,0,0,0,0,0,0,0,0,0,0,0,0,0,0,0,0,0,0,0,0,0,0,0,0,0,0,0,0,0,0,0,0,0,0,0,0,0,0,0,0,0,0,0,0,0,0,0,0,0,
		1,1,1,1,1,0,0,0,0,0,0,0,0,0,0,0,0,0,0,0,0,0,0,0,0,0,0,0,0,0,0,0,0,0,0,0,0,0,0,0,0,0,0,0,0,0,0,0,0,0,0,0,0,0,0,0,0,0,0,0,0,0,0,0,0,0,1,1,1,1,1,1,1,1,1,1,0,0,0,0,0,0,0,0,0,0,0,0,0,0,0,0,0,0,0,0,0,0,0,0,0,0,0,0,0,0,0,0,0,0,0,0,0,0,0,0,0,0,0,0,0,0,0,0,0,0,0,0,
		1,1,1,1,0,0,0,0,0,0,0,0,0,0,0,0,0,0,0,0,0,0,0,0,0,0,0,0,0,0,0,0,0,0,0,0,0,0,0,0,0,0,0,0,0,0,0,0,0,0,0,0,0,0,0,0,0,0,0,0,0,0,0,0,0,0,0,1,1,1,1,1,1,1,1,1,0,0,0,0,0,0,0,0,0,0,0,0,0,0,0,0,0,0,0,0,0,0,0,0,0,0,0,0,0,0,0,0,0,0,0,0,0,0,0,0,0,0,0,0,0,0,0,0,0,0,0,0,
		1,1,1,0,0,0,0,0,0,0,0,0,0,0,0,0,0,0,0,0,0,0,0,0,0,0,0,0,0,0,0,0,0,0,0,0,0,0,0,0,0,0,0,0,0,0,0,0,0,0,0,0,0,0,0,0,0,0,0,0,0,0,0,0,0,0,0,0,0,0,0,0,0,0,0,0,0,0,0,0,0,0,0,0,0,0,0,0,0,0,0,0,0,0,0,0,0,0,0,0,0,0,0,0,0,0,0,0,0,0,0,0,0,0,0,0,0,0,0,0,0,0,0,0,0,0,0,0,
		1,1,1,1,0,0,0,0,0,0,0,0,0,0,0,0,0,0,0,0,0,0,0,0,0,0,0,0,0,0,0,0,0,0,0,0,0,0,0,0,0,0,0,0,0,0,0,0,0,0,0,0,0,0,0,0,0,0,0,0,0,0,0,0,0,0,0,0,0,0,0,0,0,0,0,0,0,0,0,0,0,0,0,0,0,0,0,0,0,0,0,0,0,0,0,0,0,0,0,0,0,0,0,0,0,0,0,0,0,0,0,0,0,0,0,0,0,0,0,0,0,0,0,0,0,0,0,0,
		0,1,1,0,0,0,0,0,0,0,0,0,0,0,0,0,0,0,0,0,0,0,0,0,0,0,0,0,0,0,0,0,0,0,0,0,0,0,0,0,0,0,0,0,0,0,0,0,0,0,0,0,0,0,0,0,0,0,0,0,0,0,0,0,0,0,0,0,0,0,0,0,0,0,0,0,0,0,0,0,0,0,0,0,0,0,0,0,0,0,0,0,0,0,0,0,0,0,0,0,0,0,0,0,0,0,0,0,0,0,0,0,0,0,0,0,0,0,0,0,0,0,0,0,0,0,0,0,
		0,1,0,0,0,0,0,0,0,0,0,0,0,0,0,0,0,0,0,0,0,0,0,0,0,0,0,0,0,0,0,0,0,0,0,0,0,0,0,0,0,0,0,0,0,0,0,0,0,0,0,0,0,0,0,0,0,0,0,0,0,0,0,0,0,0,0,0,0,0,0,0,0,0,0,0,0,0,0,0,0,0,0,0,0,0,0,0,0,0,0,0,0,0,0,0,0,0,0,0,0,0,0,0,0,0,0,0,0,0,0,0,0,0,0,0,0,0,0,0,0,0,0,0,0,0,0,0,
		0,0,0,0,0,0,0,0,0,0,0,0,0,0,0,0,0,0,0,0,0,0,0,0,0,0,0,0,0,0,0,0,0,0,0,0,0,0,0,0,0,0,0,0,0,0,0,0,0,0,0,0,0,0,0,0,0,0,0,0,0,0,0,0,0,0,0,0,0,0,0,0,0,0,0,0,0,0,0,0,0,0,0,0,0,0,0,0,0,0,0,0,0,0,0,0,0,0,0,0,0,0,0,0,0,0,0,0,0,0,0,0,0,0,0,0,0,0,0,0,0,0,0,0,0,0,0,0,
		0,0,0,0,0,0,0,0,0,0,0,0,0,0,0,0,0,0,0,0,0,0,0,0,0,0,0,0,0,0,0,0,0,0,0,0,0,0,0,0,0,0,0,0,0,0,0,0,0,0,0,0,0,0,0,0,0,0,0,0,0,0,0,0,0,0,0,0,0,0,0,0,0,0,0,0,0,0,0,0,0,0,0,0,0,0,0,0,0,0,0,0,0,0,0,0,0,0,0,0,0,0,0,0,0,0,0,0,0,0,0,0,0,0,0,0,0,0,0,0,0,0,0,0,0,0,0,0,
		0,0,0,0,0,0,0,0,0,0,0,0,0,0,0,0,0,0,0,0,0,0,0,0,0,0,0,0,0,0,0,0,0,0,0,0,0,0,0,0,0,0,0,0,0,0,0,0,0,0,0,0,0,0,0,0,0,0,0,0,0,0,0,0,0,0,0,0,0,0,0,0,0,0,0,0,0,0,0,0,0,0,0,0,0,0,0,0,0,0,0,0,0,0,0,0,0,0,0,0,0,0,0,0,0,0,0,0,0,0,0,0,0,0,0,0,0,0,0,0,0,0,0,0,0,0,0,0,
		0,0,0,0,0,0,0,0,0,0,0,0,0,0,0,0,0,0,0,0,0,0,0,0,0,0,0,0,0,0,0,0,0,0,0,0,0,0,0,0,0,0,0,0,0,0,0,0,0,0,0,0,0,0,0,0,0,0,0,0,0,0,0,0,0,0,0,0,0,0,0,0,0,0,0,0,0,0,0,0,0,0,0,0,0,0,0,0,0,0,0,0,0,0,0,0,0,0,0,0,0,0,0,0,0,0,0,0,0,0,0,0,0,0,0,0,0,0,0,0,0,0,0,0,0,0,0,0,
		0,0,0,0,0,0,0,0,0,0,0,0,0,0,0,0,0,0,0,0,0,0,0,0,0,0,0,0,0,0,0,0,0,0,0,0,0,0,0,0,0,0,0,0,0,0,0,0,0,0,0,0,0,0,0,0,0,0,0,0,0,0,0,0,0,0,0,0,0,0,0,0,0,0,0,0,0,0,0,0,0,0,0,0,0,0,0,0,0,0,0,0,0,0,0,0,0,0,0,0,0,0,0,0,0,0,0,0,0,0,0,0,0,0,0,0,0,0,0,0,0,0,0,0,0,0,0,0,
		0,0,0,0,0,0,0,0,0,0,0,0,0,0,0,0,0,0,0,0,0,0,0,0,0,0,0,0,0,0,0,0,0,0,0,0,0,0,0,0,0,0,0,0,0,0,0,0,0,0,0,0,0,0,0,0,0,0,0,0,0,0,0,0,0,0,0,0,0,0,0,0,0,0,0,0,0,0,0,0,0,0,0,0,0,0,0,0,0,0,0,0,0,0,0,0,0,0,0,0,0,0,0,0,0,0,0,0,0,0,0,0,0,0,0,0,0,0,0,0,0,0,0,0,0,0,0,0,
		0,0,0,0,0,0,0,0,0,0,0,0,0,0,0,0,0,0,0,0,0,0,0,0,0,0,0,0,0,0,0,0,0,0,0,0,0,0,0,0,0,0,0,0,0,0,0,0,0,0,0,0,0,0,0,0,0,0,0,0,0,0,0,0,0,0,0,0,0,0,0,0,0,0,0,0,0,0,0,0,0,0,0,0,0,0,0,0,0,0,0,0,0,0,0,0,0,0,0,0,0,0,0,0,0,0,0,0,0,0,0,0,0,0,0,0,0,0,0,0,0,0,0,0,0,0,0,0,
		0,0,0,0,0,0,0,0,0,0,0,0,0,0,0,0,0,0,0,0,0,0,0,0,0,0,0,0,0,0,0,0,0,0,0,0,0,0,0,0,0,0,0,0,0,0,0,0,0,0,0,0,0,0,0,0,0,0,0,0,0,0,0,0,0,0,0,0,0,0,0,0,0,0,0,0,0,0,0,0,0,0,0,0,0,0,0,0,0,0,0,0,0,0,0,0,0,0,0,0,0,0,0,0,0,0,0,0,0,0,0,0,0,0,0,0,0,0,0,0,0,0,0,0,0,0,0,0,
		0,0,0,0,0,0,0,0,0,0,0,0,0,0,0,0,0,0,0,0,0,0,0,0,0,0,0,0,0,0,0,0,0,0,0,0,0,0,0,0,0,0,0,0,0,0,0,0,0,0,0,0,0,0,0,0,0,0,0,0,0,0,0,0,0,0,0,0,0,0,0,0,0,0,0,0,0,0,0,0,0,0,0,0,0,0,0,0,0,0,0,0,0,0,0,0,0,0,0,0,0,0,0,0,0,0,0,0,0,0,0,0,0,0,0,0,0,0,0,0,0,0,0,0,0,0,0,0,
		0,0,0,0,0,0,0,0,0,0,0,0,0,0,0,0,0,0,0,0,0,0,0,0,0,0,0,0,0,0,0,0,0,0,0,0,0,0,0,0,0,0,0,0,0,0,0,0,0,0,0,0,0,0,0,0,0,0,0,0,0,0,0,0,0,0,0,0,0,0,0,0,0,0,0,0,0,0,0,0,0,0,0,0,0,0,0,0,0,0,0,0,0,0,0,0,0,0,0,0,0,0,0,0,0,0,0,0,0,0,0,0,0,0,0,0,0,0,0,0,0,0,0,0,0,0,0,0,
		0,0,0,0,0,0,0,0,0,0,0,0,0,0,0,0,0,0,0,0,0,0,0,0,0,0,0,0,0,0,0,0,0,0,0,0,0,0,0,0,0,0,0,0,0,0,0,0,0,0,0,0,0,0,0,0,0,0,0,0,0,0,0,0,0,0,0,0,0,0,0,0,0,0,0,0,0,0,0,0,0,0,0,0,0,0,0,0,0,0,0,0,0,0,0,0,0,0,0,0,0,0,0,0,0,0,0,0,0,0,0,0,0,0,0,0,0,0,0,0,0,0,0,0,0,0,0,0,
		0,0,0,0,0,0,0,0,0,0,0,0,0,0,0,0,0,0,0,0,0,0,0,0,0,0,0,0,0,0,0,0,0,0,0,0,0,0,0,0,0,0,0,0,0,0,0,0,0,0,0,0,0,0,0,0,0,0,0,0,0,0,0,0,0,0,0,0,0,0,0,0,0,0,0,0,0,0,0,0,0,0,0,0,0,0,0,0,0,0,0,0,0,0,0,0,0,0,0,0,0,0,0,0,0,0,0,0,0,0,0,0,0,0,0,0,0,0,0,0,0,0,0,0,0,0,0,0,
		0,0,0,0,0,0,0,0,0,0,0,0,0,0,0,0,0,0,0,0,0,0,0,0,0,0,0,0,0,0,0,0,0,0,0,0,0,0,0,0,0,0,0,0,0,0,0,0,0,0,0,0,0,0,0,0,0,0,0,0,0,0,0,0,0,0,0,0,0,0,0,0,0,1,1,1,1,1,1,1,1,0,0,0,0,0,0,0,0,0,0,0,0,0,0,1,1,1,0,0,0,0,0,0,0,0,0,0,0,0,0,0,0,0,0,0,0,0,0,0,0,0,0,0,0,0,0,0,
		0,0,0,0,0,0,0,0,0,0,0,0,0,0,0,0,0,0,0,0,0,0,0,0,0,0,0,0,0,0,0,0,0,0,0,0,0,0,0,0,0,0,0,0,0,0,0,0,0,0,0,0,0,0,0,0,0,0,0,0,0,0,0,0,0,0,0,0,0,1,0,0,1,1,1,1,1,1,1,1,1,1,0,0,0,0,0,0,1,1,0,0,0,1,1,1,1,0,0,0,0,0,0,0,0,0,0,0,0,0,0,0,0,0,0,0,0,0,0,0,0,0,0,0,0,0,0,0,
		0,0,0,0,0,0,0,0,0,0,0,0,0,0,0,0,0,0,0,0,0,0,0,0,0,0,0,0,0,0,0,0,0,0,0,0,0,0,0,0,0,0,0,0,0,0,0,0,0,0,0,0,0,0,0,0,0,0,0,0,0,0,0,0,0,0,0,0,1,1,1,1,1,1,1,1,1,1,1,1,1,1,1,1,1,1,1,1,1,0,0,0,0,0,0,0,0,0,0,0,0,0,0,0,0,0,0,0,0,0,0,0,0,0,0,0,0,0,0,0,0,0,0,0,0,0,0,0,
		0,0,0,0,0,0,0,0,0,0,0,0,0,0,0,0,0,0,0,0,0,0,0,0,0,0,0,0,0,0,0,0,0,0,0,0,0,0,0,0,0,0,0,0,0,0,0,0,0,0,0,0,0,0,0,0,0,0,0,0,0,1,1,0,0,0,0,1,1,1,1,1,1,1,1,1,1,1,1,1,1,1,1,1,1,1,1,0,0,0,0,0,0,0,0,0,0,0,0,0,0,0,0,0,0,0,0,0,0,0,0,0,0,0,0,0,0,0,0,0,0,0,0,0,0,0,0,0,
		0,0,0,0,0,0,0,0,0,0,0,0,0,0,0,0,0,0,0,0,0,0,0,0,0,0,0,0,0,0,0,0,0,0,0,0,0,0,0,0,0,0,0,0,0,0,0,0,0,0,0,0,0,0,0,0,0,0,0,0,0,0,0,1,1,1,1,1,1,1,1,1,1,1,1,1,1,1,1,1,1,1,1,1,1,0,0,0,0,0,0,0,0,0,0,0,0,0,0,0,0,0,0,0,0,0,0,0,0,0,0,0,0,0,0,0,0,0,0,0,0,0,0,0,0,0,0,0,

};

const unsigned char gImage_12334[174] = { 0X00,0X02,0X15,0X00,0X1C,0X00,
0X00,0X00,0X00,0X0F,0X00,0X00,0X00,0X00,0X00,0X30,0XF0,0X00,0X00,0X00,0X00,0XC0,
0XFC,0X00,0X00,0X00,0X03,0X4F,0XFF,0XC0,0X00,0X00,0X0F,0XCF,0XC0,0X00,0X00,0X00,
0XBF,0XF3,0X00,0X00,0X00,0X03,0XFF,0XFF,0X00,0X00,0X00,0X3F,0XF0,0X0F,0X00,0X00,
0X00,0XFF,0XC0,0X0F,0XC0,0X00,0X03,0XFD,0X00,0X0F,0XC0,0X00,0X0F,0XFC,0X00,0X0F,
0XF0,0X00,0X3D,0X30,0X00,0X0C,0XFC,0X00,0X30,0XF0,0X00,0X3C,0X3C,0X00,0XC0,0XC0,
0X00,0XF0,0X0C,0X00,0X00,0XC0,0X00,0XC0,0X00,0X00,0X00,0XC0,0X00,0XC0,0X00,0X00,
0X03,0XC0,0X00,0XC0,0X00,0X00,0X03,0XC0,0X03,0XC0,0X00,0X00,0X03,0XC0,0X00,0XC0,
0X00,0X00,0X03,0XC0,0X00,0X30,0X00,0X00,0X00,0XC0,0X00,0X30,0X00,0X00,0X00,0XC0,
0X00,0X30,0X00,0X00,0X00,0XF0,0X0F,0XFF,0XC0,0X00,0X03,0XFF,0XFF,0X3F,0XC0,0X00,
0X00,0X03,0XC0,0X1C,0X00,0X00,0X00,0X03,0XC0,0X00,0X00,0X00,0X00,0X0F,0XF0,0X00,
0X00,0X00,0X00,0X00,0XC0,0X00,0X00,0X00,};

#include "main.h"

/* USER CODE BEGIN Includes */
#include "epd2in7.h"
#include "epdif.h"
#include "epdpaint.h"
#include "imagedata.h"
//#include "tupian.h"
#include <stdlib.h>
#include <stdio.h>

//#include "EPD_2in9d.h"
/* USER CODE END Includes */

SPI_HandleTypeDef hspi1;

UART_HandleTypeDef huart1;
#define COLORED      0
#define UNCOLORED    1

void SystemClock_Config(void);
 void MX_GPIO_Init(void);
 void MX_SPI1_Init(void);
 void MX_USART1_UART_Init(void);

int main(void)
{
  /* USER CODE BEGIN 1 */
	unsigned char* frame_buffer = (unsigned char*)malloc(EPD_WIDTH * EPD_HEIGHT / 8);
  /* USER CODE END 1 */

  /* MCU Configuration--------------------------------------------------------*/

  /* Reset of all peripherals, Initializes the Flash interface and the Systick. */
  HAL_Init();

  /* Configure the system clock */
  SystemClock_Config();

  /* Initialize all configured peripherals */
  MX_GPIO_Init();
  MX_SPI1_Init();
  MX_USART1_UART_Init();
  /* USER CODE BEGIN 2 */
  EPD epd;
  if (EPD_Init(&epd) != 0) {
      printf("e-Paper init failed\n");
      return -1;
    }

    Paint paint;
    Paint_Init(&paint, frame_buffer, epd.width, epd.height);
    Paint_Clear(&paint, UNCOLORED);

    /* Draw something to the frame buffer */
    /* For simplicity, the arguments are explicit numerical coordinates */
    Paint_SetRotate(&paint, ROTATE_0);
    Paint_DrawStringAt(&paint, 4, 50, "TZ", &Font20, COLORED);
    Paint_DrawRectangle(&paint, 10, 130, 50, 180, COLORED);
    Paint_DrawLine(&paint, 10, 130, 50, 180, COLORED);
    Paint_DrawLine(&paint, 50, 130, 10, 180, COLORED);
    Paint_DrawCircle(&paint, 100, 150, 25, COLORED);
    Paint_DrawFilledRectangle(&paint, 10, 200, 50, 250, COLORED);
    Paint_DrawFilledRectangle(&paint, 0, 76, 176, 96, COLORED);
    Paint_DrawFilledCircle(&paint, 100, 220, 25, COLORED);
    Paint_DrawStringAt(&paint, 18, 80, "NB!", &Font16, UNCOLORED);

    Paint_Clear(&paint, UNCOLORED);
    /* Display the frame_buffer */
    int i,j;
    //extern  *qie;
    /*FILE* fp;
	char pixbuff[37888]={0};
	fp = fopen("pixel.txt","w");
	fputs("helloworld", fp);
	fclose(fp);

    fp = fopen("pixel.txt","r");
    fscanf(fp,"%s",pixbuff);
	printf("%s",pixbuff);
	fclose(fp);

    for (i = 0; i < sizeof(pixbuff); i++){
    		if (pixbuff[i] == 1){
    		   Paint_DrawPixel(&paint, i%128,i/128,COLORED);
    }
*/

    for (i = 0; i <sizeof(qie); i++){
    		if (qie[i] == 1){
    		   Paint_DrawPixel(&paint, i%128,i/128,COLORED);
    }

    }

    /* USER CODE END 2 */

    /* Infinite loop */
    EPD_DisplayFrame(&epd, frame_buffer);
    //EPD_DisplayFrame(&epd, gImage_business_card );

  /* USER CODE END 3 */

}

void SystemClock_Config(void)
{
  RCC_OscInitTypeDef RCC_OscInitStruct = {0};
  RCC_ClkInitTypeDef RCC_ClkInitStruct = {0};
  RCC_PeriphCLKInitTypeDef PeriphClkInit = {0};

  /** Initializes the CPU, AHB and APB busses clocks
  */
  RCC_OscInitStruct.OscillatorType = RCC_OSCILLATORTYPE_HSI;
  RCC_OscInitStruct.HSIState = RCC_HSI_ON;
  RCC_OscInitStruct.HSICalibrationValue = RCC_HSICALIBRATION_DEFAULT;
  RCC_OscInitStruct.PLL.PLLState = RCC_PLL_ON;
  RCC_OscInitStruct.PLL.PLLSource = RCC_PLLSOURCE_HSI;
  RCC_OscInitStruct.PLL.PLLMUL = RCC_PLL_MUL12;
  RCC_OscInitStruct.PLL.PREDIV = RCC_PREDIV_DIV1;
  if (HAL_RCC_OscConfig(&RCC_OscInitStruct) != HAL_OK)
  {

  }
  /** Initializes the CPU, AHB and APB busses clocks
  */
  RCC_ClkInitStruct.ClockType = RCC_CLOCKTYPE_HCLK|RCC_CLOCKTYPE_SYSCLK
                              |RCC_CLOCKTYPE_PCLK1;
  RCC_ClkInitStruct.SYSCLKSource = RCC_SYSCLKSOURCE_PLLCLK;
  RCC_ClkInitStruct.AHBCLKDivider = RCC_SYSCLK_DIV1;
  RCC_ClkInitStruct.APB1CLKDivider = RCC_HCLK_DIV1;

  if (HAL_RCC_ClockConfig(&RCC_ClkInitStruct, FLASH_LATENCY_1) != HAL_OK)
  {

  }
  PeriphClkInit.PeriphClockSelection = RCC_PERIPHCLK_USART1;
  PeriphClkInit.Usart1ClockSelection = RCC_USART1CLKSOURCE_PCLK1;
  if (HAL_RCCEx_PeriphCLKConfig(&PeriphClkInit) != HAL_OK)
  {

  }
}

void MX_SPI1_Init(void)
{

  /* SPI1 parameter configuration*/
  hspi1.Instance = SPI1;
  hspi1.Init.Mode = SPI_MODE_MASTER;
  hspi1.Init.Direction = SPI_DIRECTION_2LINES;
  hspi1.Init.DataSize = SPI_DATASIZE_8BIT;
  hspi1.Init.CLKPolarity = SPI_POLARITY_LOW;
  hspi1.Init.CLKPhase = SPI_PHASE_1EDGE;
  hspi1.Init.NSS = SPI_NSS_SOFT;
  hspi1.Init.BaudRatePrescaler = SPI_BAUDRATEPRESCALER_256;
  hspi1.Init.FirstBit = SPI_FIRSTBIT_MSB;
  hspi1.Init.TIMode = SPI_TIMODE_DISABLE;
  hspi1.Init.CRCCalculation = SPI_CRCCALCULATION_DISABLE;
  hspi1.Init.CRCPolynomial = 7;
  hspi1.Init.CRCLength = SPI_CRC_LENGTH_DATASIZE;
  hspi1.Init.NSSPMode = SPI_NSS_PULSE_DISABLE;
  if (HAL_SPI_Init(&hspi1) != HAL_OK)
  {

  }

}

void MX_USART1_UART_Init(void)
{

  huart1.Instance = USART1;
  huart1.Init.BaudRate = 38400;
  huart1.Init.WordLength = UART_WORDLENGTH_8B;
  huart1.Init.StopBits = UART_STOPBITS_1;
  huart1.Init.Parity = UART_PARITY_NONE;
  huart1.Init.Mode = UART_MODE_TX_RX;
  huart1.Init.HwFlowCtl = UART_HWCONTROL_NONE;
  huart1.Init.OverSampling = UART_OVERSAMPLING_16;
  huart1.Init.OneBitSampling = UART_ONE_BIT_SAMPLE_DISABLE;
  huart1.AdvancedInit.AdvFeatureInit = UART_ADVFEATURE_NO_INIT;
  if (HAL_UART_Init(&huart1) != HAL_OK)
  {

  }

}

void MX_GPIO_Init(void)
{
  GPIO_InitTypeDef GPIO_InitStruct = {0};

  /* GPIO Ports Clock Enable */
  __HAL_RCC_GPIOC_CLK_ENABLE();
  __HAL_RCC_GPIOF_CLK_ENABLE();
  __HAL_RCC_GPIOA_CLK_ENABLE();
  __HAL_RCC_GPIOB_CLK_ENABLE();

  /*Configure GPIO pin Output Level */
  HAL_GPIO_WritePin(E_CS_GPIO_Port, E_CS_Pin, GPIO_PIN_SET);

  /*Configure GPIO pin Output Level */
  HAL_GPIO_WritePin(E_DC_GPIO_Port, E_DC_Pin, GPIO_PIN_RESET);

  /*Configure GPIO pin Output Level */
  HAL_GPIO_WritePin(E_RST_GPIO_Port, E_RST_Pin, GPIO_PIN_SET);

  /*Configure GPIO pins : PA2 PA3 */
  GPIO_InitStruct.Pin = GPIO_PIN_2|GPIO_PIN_3;
  GPIO_InitStruct.Mode = GPIO_MODE_AF_PP;
  GPIO_InitStruct.Pull = GPIO_NOPULL;
  GPIO_InitStruct.Speed = GPIO_SPEED_FREQ_HIGH;
  GPIO_InitStruct.Alternate = GPIO_AF1_USART2;
  HAL_GPIO_Init(GPIOA, &GPIO_InitStruct);

  /*Configure GPIO pins : P1_Pin P2_Pin E_BUSY_Pin */
  GPIO_InitStruct.Pin = P1_Pin|P2_Pin|E_BUSY_Pin;
  GPIO_InitStruct.Mode = GPIO_MODE_INPUT;
  GPIO_InitStruct.Pull = GPIO_PULLUP;
  HAL_GPIO_Init(GPIOB, &GPIO_InitStruct);

  /*Configure GPIO pin : E_CS_Pin */
  GPIO_InitStruct.Pin = E_CS_Pin;
  GPIO_InitStruct.Mode = GPIO_MODE_OUTPUT_PP;
  GPIO_InitStruct.Pull = GPIO_NOPULL;
  GPIO_InitStruct.Speed = GPIO_SPEED_FREQ_LOW;
  HAL_GPIO_Init(E_CS_GPIO_Port, &GPIO_InitStruct);

  /*Configure GPIO pin : E_DC_Pin */
  GPIO_InitStruct.Pin = E_DC_Pin;
  GPIO_InitStruct.Mode = GPIO_MODE_OUTPUT_PP;
  GPIO_InitStruct.Pull = GPIO_NOPULL;
  GPIO_InitStruct.Speed = GPIO_SPEED_FREQ_LOW;
  HAL_GPIO_Init(E_DC_GPIO_Port, &GPIO_InitStruct);

  /*Configure GPIO pin : E_RST_Pin */
  GPIO_InitStruct.Pin = E_RST_Pin;
  GPIO_InitStruct.Mode = GPIO_MODE_OUTPUT_PP;
  GPIO_InitStruct.Pull = GPIO_NOPULL;
  GPIO_InitStruct.Speed = GPIO_SPEED_FREQ_HIGH;
  HAL_GPIO_Init(E_RST_GPIO_Port, &GPIO_InitStruct);

  /*Configure GPIO pins : P3_Pin P4_Pin */
  GPIO_InitStruct.Pin = P3_Pin|P4_Pin;
  GPIO_InitStruct.Mode = GPIO_MODE_INPUT;
  GPIO_InitStruct.Pull = GPIO_PULLUP;
  HAL_GPIO_Init(GPIOA, &GPIO_InitStruct);

}

/************************ (C) COPYRIGHT STMicroelectronics *****END OF FILE****/
